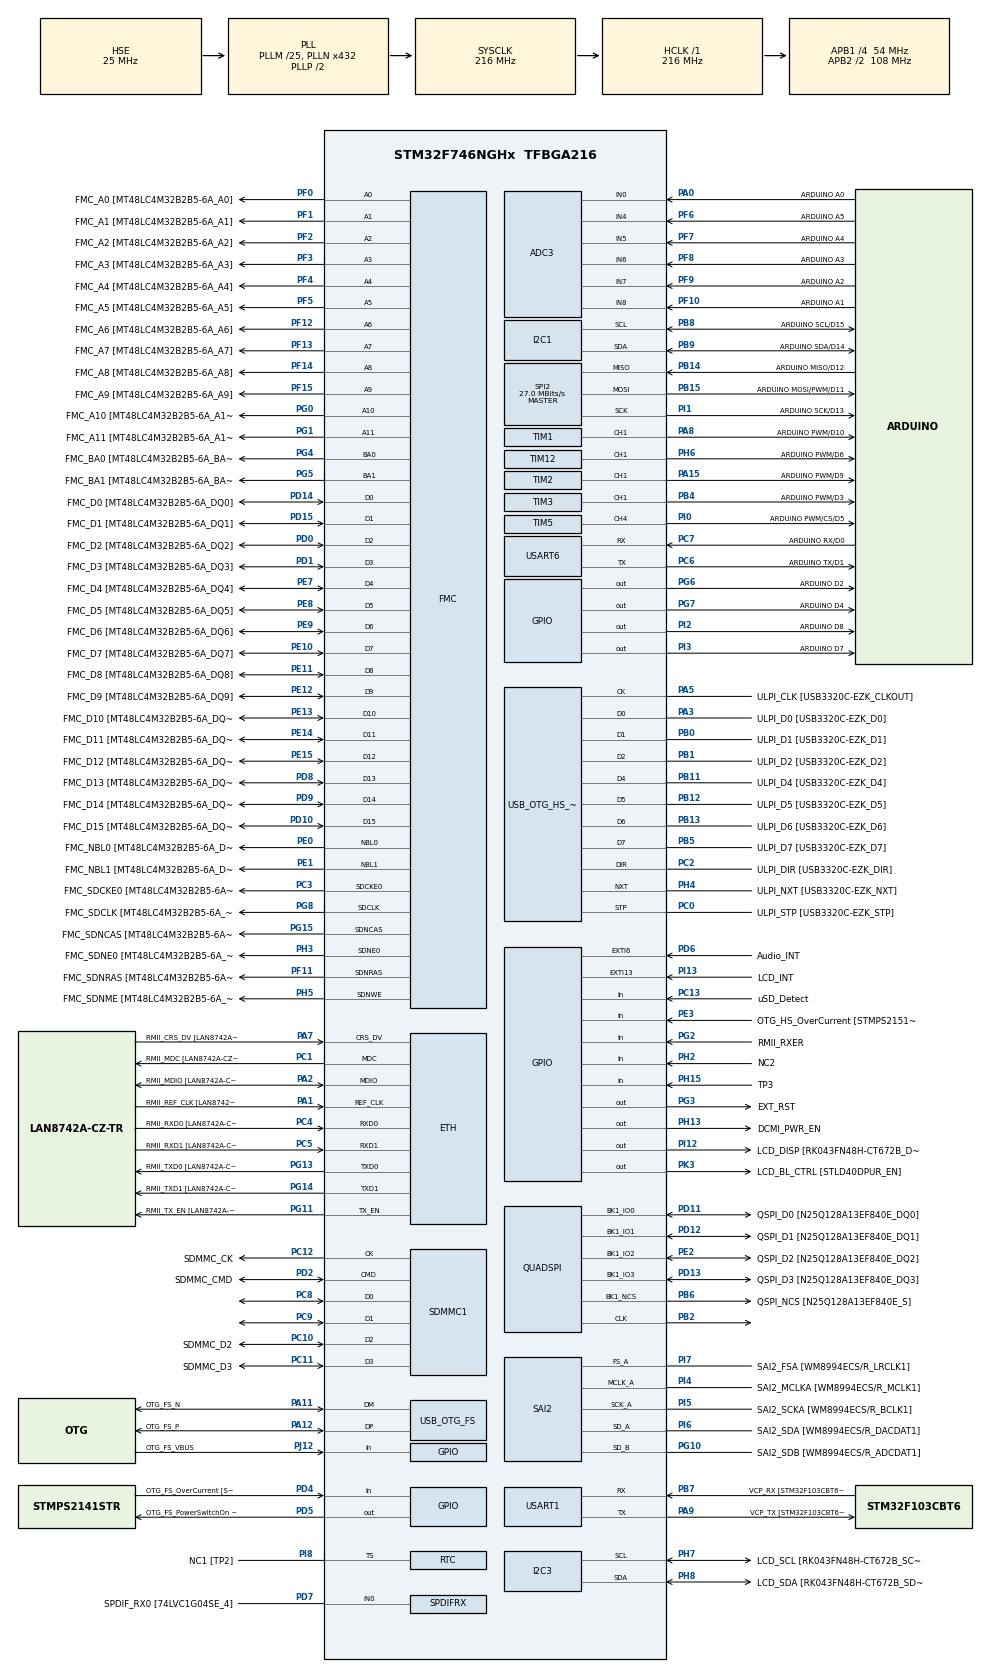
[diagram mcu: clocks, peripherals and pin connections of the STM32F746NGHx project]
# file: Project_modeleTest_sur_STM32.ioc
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ADC3.Channel=ADC_CHANNEL_7
ADC3.Channel-0\#ChannelRegularConversion=ADC_CHANNEL_4
ADC3.Channel-IN0=ADC_CHANNEL_0
ADC3.Channel-IN4=ADC_CHANNEL_4
ADC3.Channel-IN5=ADC_CHANNEL_5
ADC3.Channel-IN6=ADC_CHANNEL_6
ADC3.Channel-IN7=ADC_CHANNEL_7
ADC3.Channel-IN8=ADC_CHANNEL_8
CORTEX_M7.ART_ACCELERATOR_ENABLE=1
CORTEX_M7.CPU_DCache=Enabled
CORTEX_M7.CPU_ICache=Enabled
ETH.MediaInterface=HAL_ETH_RMII_MODE
ETH.PHY_Name=LAN8742A_PHY_ADDRESS
ETH.PHY_RESET_DELAY=0x00000FFF
ETH.PhyAddress=0
FATFS.BSP.number=1
FATFS0.BSP.STBoard=false
FATFS0.BSP.api=Unknown
FATFS0.BSP.instance=PC13
FATFS0.BSP.ip=GPIO
FATFS0.BSP.mode=Input
FATFS0.BSP.name=Detect_SDIO
FATFS0.BSP.solution=PC13
FMC.CASLatency1=FMC_SDRAM_CAS_LATENCY_3
FMC.ExitSelfRefreshDelay1=7
FMC.LoadToActiveDelay1=2
FMC.RCDDelay1=2
FMC.RPDelay1=2
FMC.RPDelay2=2
FMC.ReadBurst1=FMC_SDRAM_RBURST_ENABLE
FMC.ReadBurst2=FMC_SDRAM_RBURST_ENABLE
FMC.RowCycleDelay1=7
FMC.RowCycleDelay2=7
FMC.SDClockPeriod1=FMC_SDRAM_CLOCK_PERIOD_2
FMC.SDClockPeriod2=FMC_SDRAM_CLOCK_PERIOD_2
FMC.SelfRefreshTime1=4
FMC.WriteRecoveryTime1=3
FREERTOS.Tasks01=defaultTask,0,4096,StartDefaultTask,Default,NULL,Dynamic,NULL,NULL
FREERTOS.configCHECK_FOR_STACK_OVERFLOW=2
FREERTOS.configTOTAL_HEAP_SIZE=32768
FREERTOS.configUSE_APPLICATION_TASK_TAG=1
FREERTOS.configUSE_COUNTING_SEMAPHORES=1
FREERTOS.configUSE_IDLE_HOOK=1
FREERTOS.configUSE_MALLOC_FAILED_HOOK=1
FREERTOS.configUSE_NEWLIB_REENTRANT=0
FREERTOS.configUSE_RECURSIVE_MUTEXES=1
I2C1.Timing=0x20404768
I2C3.Timing=0x20404768
Mcu.Family=STM32F7
Mcu.Name=STM32F746NGHx
Mcu.Package=TFBGA216
NVIC.DMA2D_IRQn=true\:5\:0\:false\:false\:true\:true\:true\:true\:true
NVIC.OTG_FS_IRQn=true\:5\:0\:false\:false\:true\:true\:true\:true\:true
NVIC.PriorityGroup=NVIC_PRIORITYGROUP_4
NVIC.TIM6_DAC_IRQn=true\:0\:0\:false\:false\:true\:false\:false\:true\:true
NVIC.TimeBase=TIM6_DAC_IRQn
NVIC.TimeBaseIP=TIM6
PA0/WKUP.GPIO_Label=ARDUINO A0
PA0/WKUP.GPIO_Mode=GPIO_MODE_ANALOG
PA0/WKUP.GPIO_PuPd=GPIO_NOPULL
PA0/WKUP.Signal=ADCx_IN0
PA1.GPIO_Label=RMII_REF_CLK [LAN8742A-CZ-TR_REFCLK0]
PA1.Mode=RMII
PA1.Signal=ETH_REF_CLK
PA10.GPIO_Label=OTG_FS_ID
PA10.Signal=USB_OTG_FS_ID
PA11.GPIO_Label=OTG_FS_N
PA11.Mode=Host_Only
PA11.Signal=USB_OTG_FS_DM
PA12.GPIO_Label=OTG_FS_P
PA12.Mode=Host_Only
PA12.Signal=USB_OTG_FS_DP
PA13.GPIO_Label=SWDIO
PA13.Mode=Serial_Wire
PA13.Signal=SYS_JTMS-SWDIO
PA14.GPIO_Label=SWCLK
PA14.Mode=Serial_Wire
PA14.Signal=SYS_JTCK-SWCLK
PA15.GPIO_Label=ARDUINO PWM/D9
PA15.GPIO_ModeDefaultPP=GPIO_MODE_AF_PP
PA15.GPIO_PuPd=GPIO_NOPULL
PA15.GPIO_Speed=GPIO_SPEED_FREQ_LOW
PA15.Signal=S_TIM2_CH1_ETR
PA2.GPIO_Label=RMII_MDIO [LAN8742A-CZ-TR_MDIO]
PA2.Mode=RMII
PA2.Signal=ETH_MDIO
PA3.GPIO_Label=ULPI_D0 [USB3320C-EZK_D0]
PA3.Mode=Host_HS
PA3.Signal=USB_OTG_HS_ULPI_D0
PA4.GPIO_Label=DCMI_HSYNC
PA4.Signal=DCMI_HSYNC
PA5.GPIO_Label=ULPI_CLK [USB3320C-EZK_CLKOUT]
PA5.Mode=Host_HS
PA5.Signal=USB_OTG_HS_ULPI_CK
PA6.Signal=DCMI_PIXCLK
PA7.GPIO_Label=RMII_CRS_DV [LAN8742A-CZ-TR_CRS_DV]
PA7.Mode=RMII
PA7.Signal=ETH_CRS_DV
PA8.GPIO_Label=ARDUINO PWM/D10
PA8.GPIO_ModeDefaultPP=GPIO_MODE_AF_PP
PA8.GPIO_PuPd=GPIO_NOPULL
PA8.GPIO_Speed=GPIO_SPEED_FREQ_LOW
PA8.Signal=S_TIM1_CH1
PA9.GPIO_Label=VCP_TX [STM32F103CBT6_PA3]
PA9.GPIO_Mode=GPIO_MODE_AF_PP
PA9.GPIO_PuPd=GPIO_NOPULL
PA9.GPIO_Speed=GPIO_SPEED_FREQ_LOW
PA9.Mode=Asynchronous
PA9.Signal=USART1_TX
PB0.GPIO_Label=ULPI_D1 [USB3320C-EZK_D1]
PB0.Mode=Host_HS
PB0.Signal=USB_OTG_HS_ULPI_D1
PB1.GPIO_Label=ULPI_D2 [USB3320C-EZK_D2]
PB1.Mode=Host_HS
PB1.Signal=USB_OTG_HS_ULPI_D2
PB10.GPIO_Label=ULPI_D3 [USB3320C-EZK_D3]
PB10.Signal=USB_OTG_HS_ULPI_D3
PB11.GPIO_Label=ULPI_D4 [USB3320C-EZK_D4]
PB11.Mode=Host_HS
PB11.Signal=USB_OTG_HS_ULPI_D4
PB12.GPIO_Label=ULPI_D5 [USB3320C-EZK_D5]
PB12.Mode=Host_HS
PB12.Signal=USB_OTG_HS_ULPI_D5
PB13.GPIO_Label=ULPI_D6 [USB3320C-EZK_D6]
PB13.Mode=Host_HS
PB13.Signal=USB_OTG_HS_ULPI_D6
PB14.GPIO_Label=ARDUINO MISO/D12
PB14.GPIO_Mode=GPIO_MODE_AF_PP
PB14.GPIO_PuPd=GPIO_NOPULL
PB14.GPIO_Speed=GPIO_SPEED_FREQ_LOW
PB14.Mode=Full_Duplex_Master
PB14.Signal=SPI2_MISO
PB15.GPIO_Label=ARDUINO MOSI/PWM/D11
PB15.GPIO_Mode=GPIO_MODE_AF_PP
PB15.GPIO_PuPd=GPIO_NOPULL
PB15.GPIO_Speed=GPIO_SPEED_FREQ_LOW
PB15.Mode=Full_Duplex_Master
PB15.Signal=SPI2_MOSI
PB2.Mode=Single Bank 1
PB2.Signal=QUADSPI_CLK
PB3.GPIO_Label=SWO
PB3.Signal=SYS_JTDO-SWO
PB4.GPIO_Label=ARDUINO PWM/D3
PB4.GPIO_ModeDefaultPP=GPIO_MODE_AF_PP
PB4.GPIO_PuPd=GPIO_NOPULL
PB4.GPIO_Speed=GPIO_SPEED_FREQ_LOW
PB4.Signal=S_TIM3_CH1
PB5.GPIO_Label=ULPI_D7 [USB3320C-EZK_D7]
PB5.Mode=Host_HS
PB5.Signal=USB_OTG_HS_ULPI_D7
PB6.GPIO_Label=QSPI_NCS [N25Q128A13EF840E_S]
PB6.Mode=Single Bank 1
PB6.Signal=QUADSPI_BK1_NCS
PB7.GPIO_Label=VCP_RX [STM32F103CBT6_PA2]
PB7.GPIO_Mode=GPIO_MODE_AF_PP
PB7.GPIO_PuPd=GPIO_NOPULL
PB7.GPIO_Speed=GPIO_SPEED_FREQ_LOW
PB7.Mode=Asynchronous
PB7.Signal=USART1_RX
PB8.GPIO_Label=ARDUINO SCL/D15
PB8.GPIO_Mode=GPIO_MODE_AF_OD
PB8.GPIO_Pu=GPIO_PULLUP
PB8.GPIO_PuPd=GPIO_NOPULL
PB8.GPIO_Speed=GPIO_SPEED_FREQ_LOW
PB8.Mode=I2C
PB8.Signal=I2C1_SCL
PB9.GPIO_Label=ARDUINO SDA/D14
PB9.GPIO_Mode=GPIO_MODE_AF_OD
PB9.GPIO_Pu=GPIO_PULLUP
PB9.GPIO_PuPd=GPIO_NOPULL
PB9.GPIO_Speed=GPIO_SPEED_FREQ_LOW
PB9.Mode=I2C
PB9.Signal=I2C1_SDA
PC0.GPIO_Label=ULPI_STP [USB3320C-EZK_STP]
PC0.Mode=Host_HS
PC0.Signal=USB_OTG_HS_ULPI_STP
PC1.GPIO_Label=RMII_MDC [LAN8742A-CZ-TR_MDC]
PC1.Mode=RMII
PC1.Signal=ETH_MDC
PC10.GPIO_Label=SDMMC_D2
PC10.Mode=SD_4_bits_Wide_bus
PC10.Signal=SDMMC1_D2
PC11.GPIO_Label=SDMMC_D3
PC11.Mode=SD_4_bits_Wide_bus
PC11.Signal=SDMMC1_D3
PC12.GPIO_Label=SDMMC_CK
PC12.Mode=SD_4_bits_Wide_bus
PC12.Signal=SDMMC1_CK
PC13.GPIO_Label=uSD_Detect
PC13.Signal=GPIO_Input
PC14/OSC32_IN.GPIO_Label=RCC_OSC32_IN
PC14/OSC32_IN.Mode=LSE-External-Oscillator
PC14/OSC32_IN.Signal=RCC_OSC32_IN
PC15/OSC32_OUT.GPIO_Label=RCC_OSC32_OUT
PC15/OSC32_OUT.Mode=LSE-External-Oscillator
PC15/OSC32_OUT.Signal=RCC_OSC32_OUT
PC2.GPIO_Label=ULPI_DIR [USB3320C-EZK_DIR]
PC2.Mode=Host_HS
PC2.Signal=USB_OTG_HS_ULPI_DIR
PC3.GPIO_Label=FMC_SDCKE0 [MT48LC4M32B2B5-6A_CKE]
PC3.Mode=SdramChipSelect1_1
PC3.Signal=FMC_SDCKE0
PC4.GPIO_Label=RMII_RXD0 [LAN8742A-CZ-TR_RXD0]
PC4.Mode=RMII
PC4.Signal=ETH_RXD0
PC5.GPIO_Label=RMII_RXD1 [LAN8742A-CZ-TR_RXD1]
PC5.Mode=RMII
PC5.Signal=ETH_RXD1
PC6.GPIO_Label=ARDUINO TX/D1
PC6.Mode=Asynchronous
PC6.Signal=USART6_TX
PC7.GPIO_Label=ARDUINO RX/D0
PC7.Mode=Asynchronous
PC7.Signal=USART6_RX
PC8.Mode=SD_4_bits_Wide_bus
PC8.Signal=SDMMC1_D0
PC9.Mode=SD_4_bits_Wide_bus
PC9.Signal=SDMMC1_D1
PD0.GPIO_Label=FMC_D2 [MT48LC4M32B2B5-6A_DQ2]
PD0.Signal=FMC_D2_DA2
PD1.GPIO_Label=FMC_D3 [MT48LC4M32B2B5-6A_DQ3]
PD1.Signal=FMC_D3_DA3
PD10.GPIO_Label=FMC_D15 [MT48LC4M32B2B5-6A_DQ15]
PD10.Signal=FMC_D15_DA15
PD11.GPIO_Label=QSPI_D0 [N25Q128A13EF840E_DQ0]
PD11.Mode=Single Bank 1
PD11.Signal=QUADSPI_BK1_IO0
PD12.GPIO_Label=QSPI_D1 [N25Q128A13EF840E_DQ1]
PD12.Mode=Single Bank 1
PD12.Signal=QUADSPI_BK1_IO1
PD13.GPIO_Label=QSPI_D3 [N25Q128A13EF840E_DQ3]
PD13.Mode=Single Bank 1
PD13.Signal=QUADSPI_BK1_IO3
PD14.GPIO_Label=FMC_D0 [MT48LC4M32B2B5-6A_DQ0]
PD14.Signal=FMC_D0_DA0
PD15.GPIO_Label=FMC_D1 [MT48LC4M32B2B5-6A_DQ1]
PD15.Signal=FMC_D1_DA1
PD2.GPIO_Label=SDMMC_CMD
PD2.Mode=SD_4_bits_Wide_bus
PD2.Signal=SDMMC1_CMD
PD3.GPIO_Label=DCMI_D5
PD3.Signal=DCMI_D5
PD4.GPIO_Label=OTG_FS_OverCurrent [STMPS2141STR_Fault]
PD4.Signal=GPIO_Input
PD5.GPIO_Label=OTG_FS_PowerSwitchOn [STMPS2141STR_EN]
PD5.PinState=GPIO_PIN_SET
PD5.Signal=GPIO_Output
PD6.GPIO_Label=Audio_INT
PD6.GPIO_ModeDefaultEXTI=GPIO_MODE_EVT_RISING
PD6.Signal=GPXTI6
PD7.GPIO_Label=SPDIF_RX0 [74LVC1G04SE_4]
PD7.Mode=IN0
PD7.Signal=SPDIFRX_IN0
PD8.GPIO_Label=FMC_D13 [MT48LC4M32B2B5-6A_DQ13]
PD8.Signal=FMC_D13_DA13
PD9.GPIO_Label=FMC_D14 [MT48LC4M32B2B5-6A_DQ14]
PD9.Signal=FMC_D14_DA14
PE0.GPIO_Label=FMC_NBL0 [MT48LC4M32B2B5-6A_DQM0]
PE0.Signal=FMC_NBL0
PE1.GPIO_Label=FMC_NBL1 [MT48LC4M32B2B5-6A_DQM1]
PE1.Signal=FMC_NBL1
PE10.GPIO_Label=FMC_D7 [MT48LC4M32B2B5-6A_DQ7]
PE10.Signal=FMC_D7_DA7
PE11.GPIO_Label=FMC_D8 [MT48LC4M32B2B5-6A_DQ8]
PE11.Signal=FMC_D8_DA8
PE12.GPIO_Label=FMC_D9 [MT48LC4M32B2B5-6A_DQ9]
PE12.Signal=FMC_D9_DA9
PE13.GPIO_Label=FMC_D10 [MT48LC4M32B2B5-6A_DQ10]
PE13.Signal=FMC_D10_DA10
PE14.GPIO_Label=FMC_D11 [MT48LC4M32B2B5-6A_DQ11]
PE14.Signal=FMC_D11_DA11
PE15.GPIO_Label=FMC_D12 [MT48LC4M32B2B5-6A_DQ12]
PE15.Signal=FMC_D12_DA12
PE2.GPIO_Label=QSPI_D2 [N25Q128A13EF840E_DQ2]
PE2.Mode=Single Bank 1
PE2.Signal=QUADSPI_BK1_IO2
PE3.GPIO_Label=OTG_HS_OverCurrent [STMPS2151STR_FAULT]
PE3.Signal=GPIO_Input
PE4.GPIO_Label=LCD_B0 [RK043FN48H-CT672B_B0]
PE4.Signal=LTDC_B0
PE5.GPIO_Label=DCMI_D6
PE5.Signal=DCMI_D6
PE6.GPIO_Label=DCMI_D7
PE6.Signal=DCMI_D7
PE7.GPIO_Label=FMC_D4 [MT48LC4M32B2B5-6A_DQ4]
PE7.Signal=FMC_D4_DA4
PE8.GPIO_Label=FMC_D5 [MT48LC4M32B2B5-6A_DQ5]
PE8.Signal=FMC_D5_DA5
PE9.GPIO_Label=FMC_D6 [MT48LC4M32B2B5-6A_DQ6]
PE9.Signal=FMC_D6_DA6
PF0.GPIO_Label=FMC_A0 [MT48LC4M32B2B5-6A_A0]
PF0.Signal=FMC_A0
PF1.GPIO_Label=FMC_A1 [MT48LC4M32B2B5-6A_A1]
PF1.Signal=FMC_A1
PF10.GPIO_Label=ARDUINO A1
PF10.GPIO_Mode=GPIO_MODE_ANALOG
PF10.GPIO_PuPd=GPIO_NOPULL
PF10.Mode=IN8
PF10.Signal=ADC3_IN8
PF11.GPIO_Label=FMC_SDNRAS [MT48LC4M32B2B5-6A_RAS]
PF11.Signal=FMC_SDNRAS
PF12.GPIO_Label=FMC_A6 [MT48LC4M32B2B5-6A_A6]
PF12.Signal=FMC_A6
PF13.GPIO_Label=FMC_A7 [MT48LC4M32B2B5-6A_A7]
PF13.Signal=FMC_A7
PF14.GPIO_Label=FMC_A8 [MT48LC4M32B2B5-6A_A8]
PF14.Signal=FMC_A8
PF15.GPIO_Label=FMC_A9 [MT48LC4M32B2B5-6A_A9]
PF15.Signal=FMC_A9
PF2.GPIO_Label=FMC_A2 [MT48LC4M32B2B5-6A_A2]
PF2.Signal=FMC_A2
PF3.GPIO_Label=FMC_A3 [MT48LC4M32B2B5-6A_A3]
PF3.Signal=FMC_A3
PF4.GPIO_Label=FMC_A4 [MT48LC4M32B2B5-6A_A4]
PF4.Signal=FMC_A4
PF5.GPIO_Label=FMC_A5 [MT48LC4M32B2B5-6A_A5]
PF5.Signal=FMC_A5
PF6.GPIO_Label=ARDUINO A5
PF6.GPIO_Mode=GPIO_MODE_ANALOG
PF6.GPIO_PuPd=GPIO_NOPULL
PF6.Mode=IN4
PF6.Signal=ADC3_IN4
PF7.GPIO_Label=ARDUINO A4
PF7.GPIO_Mode=GPIO_MODE_ANALOG
PF7.GPIO_PuPd=GPIO_NOPULL
PF7.Mode=IN5
PF7.Signal=ADC3_IN5
PF8.GPIO_Label=ARDUINO A3
PF8.GPIO_Mode=GPIO_MODE_ANALOG
PF8.GPIO_PuPd=GPIO_NOPULL
PF8.Mode=IN6
PF8.Signal=ADC3_IN6
PF9.GPIO_Label=ARDUINO A2
PF9.GPIO_Mode=GPIO_MODE_ANALOG
PF9.GPIO_PuPd=GPIO_NOPULL
PF9.Mode=IN7
PF9.Signal=ADC3_IN7
PG0.GPIO_Label=FMC_A10 [MT48LC4M32B2B5-6A_A10]
PG0.Signal=FMC_A10
PG1.GPIO_Label=FMC_A11 [MT48LC4M32B2B5-6A_A11]
PG1.Signal=FMC_A11
PG10.GPIO_Label=SAI2_SDB [WM8994ECS/R_ADCDAT1]
PG10.Mode=SAI_B_SyncSlave
PG10.Signal=SAI2_SD_B
PG11.GPIO_Label=RMII_TX_EN [LAN8742A-CZ-TR_TXEN]
PG11.Mode=RMII
PG11.Signal=ETH_TX_EN
PG12.GPIO_Label=LCD_B4 [RK043FN48H-CT672B_B4]
PG12.Signal=LTDC_B4
PG13.GPIO_Label=RMII_TXD0 [LAN8742A-CZ-TR_TXD0]
PG13.Mode=RMII
PG13.Signal=ETH_TXD0
PG14.GPIO_Label=RMII_TXD1 [LAN8742A-CZ-TR_TXD1]
PG14.Mode=RMII
PG14.Signal=ETH_TXD1
PG15.GPIO_Label=FMC_SDNCAS [MT48LC4M32B2B5-6A_CAS]
PG15.Signal=FMC_SDNCAS
PG2.GPIO_Label=RMII_RXER
PG2.Signal=GPIO_Input
PG3.GPIO_Label=EXT_RST
PG3.Signal=GPIO_Output
PG4.GPIO_Label=FMC_BA0 [MT48LC4M32B2B5-6A_BA0]
PG4.Signal=FMC_A14_BA0
PG5.GPIO_Label=FMC_BA1 [MT48LC4M32B2B5-6A_BA1]
PG5.Signal=FMC_A15_BA1
PG6.GPIO_Label=ARDUINO D2
PG6.Signal=GPIO_Output
PG7.GPIO_Label=ARDUINO D4
PG7.Signal=GPIO_Output
PG8.GPIO_Label=FMC_SDCLK [MT48LC4M32B2B5-6A_CLK]
PG8.Signal=FMC_SDCLK
PG9.GPIO_Label=DCMI_VSYNC
PG9.Signal=DCMI_VSYNC
PH0/OSC_IN.GPIO_Label=OSC_25M [NZ2520SB-25.00M_OUT]
PH0/OSC_IN.Mode=HSE-External-Oscillator
PH0/OSC_IN.Signal=RCC_OSC_IN
PH1/OSC_OUT.Mode=HSE-External-Oscillator
PH1/OSC_OUT.Signal=RCC_OSC_OUT
PH10.GPIO_Label=DCMI_D1
PH10.Signal=DCMI_D1
PH11.GPIO_Label=DCMI_D2
PH11.Signal=DCMI_D2
PH12.GPIO_Label=DCMI_D3
PH12.Signal=DCMI_D3
PH13.GPIO_Label=DCMI_PWR_EN
PH13.Signal=GPIO_Output
PH14.GPIO_Label=DCMI_D4
PH14.Signal=DCMI_D4
PH15.GPIO_Label=TP3
PH15.Signal=GPIO_Input
PH2.GPIO_Label=NC2
PH2.Signal=GPIO_Input
PH3.GPIO_Label=FMC_SDNE0 [MT48LC4M32B2B5-6A_CS]
PH3.Mode=SdramChipSelect1_1
PH3.Signal=FMC_SDNE0
PH4.GPIO_Label=ULPI_NXT [USB3320C-EZK_NXT]
PH4.Mode=Host_HS
PH4.Signal=USB_OTG_HS_ULPI_NXT
PH5.GPIO_Label=FMC_SDNME [MT48LC4M32B2B5-6A_WE]
PH5.Signal=FMC_SDNWE
PH6.GPIO_Label=ARDUINO PWM/D6
PH6.Signal=S_TIM12_CH1
PH7.GPIO_Label=LCD_SCL [RK043FN48H-CT672B_SCL]
PH7.GPIO_Pu=GPIO_PULLUP
PH7.Mode=I2C
PH7.Signal=I2C3_SCL
PH8.GPIO_Label=LCD_SDA [RK043FN48H-CT672B_SDA]
PH8.GPIO_Pu=GPIO_PULLUP
PH8.Mode=I2C
PH8.Signal=I2C3_SDA
PH9.GPIO_Label=DCMI_D0
PH9.Signal=DCMI_D0
PI0.GPIO_Label=ARDUINO PWM/CS/D5
PI0.GPIO_ModeDefaultPP=GPIO_MODE_AF_PP
PI0.GPIO_PuPd=GPIO_NOPULL
PI0.GPIO_Speed=GPIO_SPEED_FREQ_LOW
PI0.Signal=S_TIM5_CH4
PI1.GPIO_Label=ARDUINO SCK/D13
PI1.GPIO_Mode=GPIO_MODE_AF_PP
PI1.GPIO_PuPd=GPIO_NOPULL
PI1.GPIO_Speed=GPIO_SPEED_FREQ_LOW
PI1.Mode=Full_Duplex_Master
PI1.Signal=SPI2_SCK
PI10.GPIO_Label=LCD_HSYNC [RK043FN48H-CT672B_HSYNC]
PI10.Signal=LTDC_HSYNC
PI12.GPIO_Label=LCD_DISP [RK043FN48H-CT672B_DISP] 
PI12.PinState=GPIO_PIN_SET
PI12.Signal=GPIO_Output
PI13.GPIO_Label=LCD_INT
PI13.GPIO_ModeDefaultEXTI=GPIO_MODE_EVT_RISING
PI13.Signal=GPXTI13
PI14.GPIO_Label=LCD_CLK [RK043FN48H-CT672B_CLK]
PI14.Signal=LTDC_CLK
PI15.GPIO_Label=LCD_R0 [RK043FN48H-CT672B_R0]
PI15.Signal=LTDC_R0
PI2.GPIO_Label=ARDUINO D8
PI2.Signal=GPIO_Output
PI3.GPIO_Label=ARDUINO D7
PI3.Signal=GPIO_Output
PI4.GPIO_Label=SAI2_MCLKA [WM8994ECS/R_MCLK1]
PI4.Mode=SAI_A_MasterWithClock
PI4.Signal=SAI2_MCLK_A
PI5.GPIO_Label=SAI2_SCKA [WM8994ECS/R_BCLK1]
PI5.Mode=SAI_A_MasterWithClock
PI5.Signal=SAI2_SCK_A
PI6.GPIO_Label=SAI2_SDA [WM8994ECS/R_DACDAT1]
PI6.Mode=SAI_A_MasterWithClock
PI6.Signal=SAI2_SD_A
PI7.GPIO_Label=SAI2_FSA [WM8994ECS/R_LRCLK1]
PI7.Mode=SAI_A_MasterWithClock
PI7.Signal=SAI2_FS_A
PI8.GPIO_Label=NC1 [TP2]
PI8.Mode=Timestamp enabled - Input Enabled to TS
PI8.Signal=RTC_TS
PI9.GPIO_Label=LCD_VSYNC [RK043FN48H-CT672B_VSYNC]
PI9.Signal=LTDC_VSYNC
PJ0.GPIO_Label=LCD_R1 [RK043FN48H-CT672B_R1]
PJ0.Signal=LTDC_R1
PJ1.GPIO_Label=LCD_R2 [RK043FN48H-CT672B_R2]
PJ1.Signal=LTDC_R2
PJ10.GPIO_Label=LCD_G3 [RK043FN48H-CT672B_G3]
PJ10.Signal=LTDC_G3
PJ11.GPIO_Label=LCD_G4 [RK043FN48H-CT672B_G4]
PJ11.Signal=LTDC_G4
PJ12.GPIO_Label=OTG_FS_VBUS
PJ12.Signal=GPIO_Input
PJ13.GPIO_Label=LCD_B1 [RK043FN48H-CT672B_B1]
PJ13.Signal=LTDC_B1
PJ14.GPIO_Label=LCD_B2 [RK043FN48H-CT672B_B2]
PJ14.Signal=LTDC_B2
PJ15.GPIO_Label=LCD_B3 [RK043FN48H-CT672B_B3]
PJ15.Signal=LTDC_B3
PJ2.GPIO_Label=LCD_R3 [RK043FN48H-CT672B_R3]
PJ2.Signal=LTDC_R3
PJ3.GPIO_Label=LCD_R4 [RK043FN48H-CT672B_R4]
PJ3.Signal=LTDC_R4
PJ4.GPIO_Label=LCD_R5 [RK043FN48H-CT672B_R5]
PJ4.Signal=LTDC_R5
PJ5.GPIO_Label=LCD_R6 [RK043FN48H-CT672B_R6]
PJ5.Signal=LTDC_R6
PJ6.GPIO_Label=LCD_R7 [RK043FN48H-CT672B_R7]
PJ6.Signal=LTDC_R7
PJ7.GPIO_Label=LCD_G0 [RK043FN48H-CT672B_G0]
PJ7.Signal=LTDC_G0
PJ8.GPIO_Label=LCD_G1 [RK043FN48H-CT672B_G1]
PJ8.Signal=LTDC_G1
PJ9.GPIO_Label=LCD_G2 [RK043FN48H-CT672B_G2]
PJ9.Signal=LTDC_G2
PK0.GPIO_Label=LCD_G5 [RK043FN48H-CT672B_G5]
PK0.Signal=LTDC_G5
PK1.GPIO_Label=LCD_G6 [RK043FN48H-CT672B_G6]
PK1.Signal=LTDC_G6
PK2.GPIO_Label=LCD_G7 [RK043FN48H-CT672B_G7]
PK2.Signal=LTDC_G7
PK3.GPIO_Label=LCD_BL_CTRL [STLD40DPUR_EN]
PK3.GPIO_Speed=GPIO_SPEED_FREQ_LOW
PK3.PinState=GPIO_PIN_SET
PK3.Signal=GPIO_Output
PK4.GPIO_Label=LCD_B5 [RK043FN48H-CT672B_B5]
PK4.Signal=LTDC_B5
PK5.GPIO_Label=LCD_B6 [RK043FN48H-CT672B_B6]
PK5.Signal=LTDC_B6
PK6.GPIO_Label=LCD_B7 [RK043FN48H-CT672B_B7]
PK6.Signal=LTDC_B7
PK7.GPIO_Label=LCD_DE [RK043FN48H-CT672B_DE]
PK7.Signal=LTDC_DE
ProjectManager.HeapSize=0x2000
ProjectManager.StackSize=0x800
ProjectManager.TargetToolchain=STM32CubeIDE
QUADSPI.ChipSelectHighTime=QSPI_CS_HIGH_TIME_6_CYCLE
QUADSPI.ClockPrescaler=1
QUADSPI.FifoThreshold=4
QUADSPI.FlashSize=24
QUADSPI.SampleShifting=QSPI_SAMPLE_SHIFTING_HALFCYCLE
RCC.AHBFreq_Value=216000000
RCC.APB1CLKDivider=RCC_HCLK_DIV4
RCC.APB1Freq_Value=54000000
RCC.APB1TimFreq_Value=108000000
RCC.APB2CLKDivider=RCC_HCLK_DIV2
RCC.APB2Freq_Value=108000000
RCC.APB2TimFreq_Value=216000000
RCC.CortexFreq_Value=216000000
RCC.HCLKFreq_Value=216000000
RCC.HSE_VALUE=25000000
RCC.HSI_VALUE=16000000
RCC.PLL48CLockSelection=RCC_CLK48SOURCE_PLLSAIP
RCC.PLLI2SN=100
RCC.PLLM=25
RCC.PLLN=432
RCC.PLLP=2
RCC.PLLQ=9
RCC.PLLSAIN=384
RCC.PLLSAIP=RCC_PLLSAIP_DIV8
RCC.PLLSAIR=5
RCC.PLLSAIRDiv=RCC_PLLSAIDIVR_8
RCC.SDMMCClockSelection=RCC_SDMMC1CLKSOURCE_CLK48
RCC.SYSCLKFreq_VALUE=216000000
RCC.SYSCLKSource=RCC_SYSCLKSOURCE_PLLCLK
RCC.USBFreq_Value=48000000
RCC.VCOOutputFreq_Value=432000000
RTC.Alarm-Alarm\ A=RTC_ALARM_A
RTC.Alarm_B-Alarm\ B=RTC_ALARM_B
SAI2.ErrorAudioFreq-SAI_A_MasterWithClock=-2.34 %
SAI2.Instance-SAI_A_MasterWithClock=SAI$Index_Block_A
SAI2.Instance-SAI_B_SyncSlave=SAI$Index_Block_B
SAI2.MClockEnable-SAI_A_MasterWithClock=SAI_MASTERCLOCK_ENABLE
SAI2.RealAudioFreq-SAI_A_MasterWithClock=187.5 KHz
SAI2.Synchro-SAI_B_SyncSlave=SAI_SYNCHRONOUS
SAI2.VirtualMode-SAI_A_MasterWithClock=VM_MASTER
SAI2.VirtualMode-SAI_B_SyncSlave=VM_SLAVE
SDMMC1.WideMode=SDMMC_BUS_WIDE_4B
SH.ADCx_IN0.0=ADC3_IN0,IN0
SH.FMC_A0.0=FMC_A0,12b-sda1
SH.FMC_A1.0=FMC_A1,12b-sda1
SH.FMC_A10.0=FMC_A10,12b-sda1
SH.FMC_A11.0=FMC_A11,12b-sda1
SH.FMC_A14_BA0.0=FMC_BA0,FourSdramBanks1
SH.FMC_A15_BA1.0=FMC_BA1,FourSdramBanks1
SH.FMC_A2.0=FMC_A2,12b-sda1
SH.FMC_A3.0=FMC_A3,12b-sda1
SH.FMC_A4.0=FMC_A4,12b-sda1
SH.FMC_A5.0=FMC_A5,12b-sda1
SH.FMC_A6.0=FMC_A6,12b-sda1
SH.FMC_A7.0=FMC_A7,12b-sda1
SH.FMC_A8.0=FMC_A8,12b-sda1
SH.FMC_A9.0=FMC_A9,12b-sda1
SH.FMC_D0_DA0.0=FMC_D0,sd-16b-d1
SH.FMC_D10_DA10.0=FMC_D10,sd-16b-d1
SH.FMC_D11_DA11.0=FMC_D11,sd-16b-d1
SH.FMC_D12_DA12.0=FMC_D12,sd-16b-d1
SH.FMC_D13_DA13.0=FMC_D13,sd-16b-d1
SH.FMC_D14_DA14.0=FMC_D14,sd-16b-d1
SH.FMC_D15_DA15.0=FMC_D15,sd-16b-d1
SH.FMC_D1_DA1.0=FMC_D1,sd-16b-d1
SH.FMC_D2_DA2.0=FMC_D2,sd-16b-d1
SH.FMC_D3_DA3.0=FMC_D3,sd-16b-d1
SH.FMC_D4_DA4.0=FMC_D4,sd-16b-d1
SH.FMC_D5_DA5.0=FMC_D5,sd-16b-d1
SH.FMC_D6_DA6.0=FMC_D6,sd-16b-d1
SH.FMC_D7_DA7.0=FMC_D7,sd-16b-d1
SH.FMC_D8_DA8.0=FMC_D8,sd-16b-d1
SH.FMC_D9_DA9.0=FMC_D9,sd-16b-d1
SH.FMC_NBL0.0=FMC_NBL0,Sd2ByteEnable1
SH.FMC_NBL1.0=FMC_NBL1,Sd2ByteEnable1
SH.FMC_SDCLK.0=FMC_SDCLK,12b-sda1
SH.FMC_SDNCAS.0=FMC_SDNCAS,12b-sda1
SH.FMC_SDNRAS.0=FMC_SDNRAS,12b-sda1
SH.FMC_SDNWE.0=FMC_SDNWE,12b-sda1
SH.S_TIM12_CH1.0=TIM12_CH1,PWM Generation1 CH1
SH.S_TIM1_CH1.0=TIM1_CH1,PWM Generation1 CH1
SH.S_TIM2_CH1_ETR.0=TIM2_CH1,PWM Generation1 CH1
SH.S_TIM3_CH1.0=TIM3_CH1,PWM Generation1 CH1
SH.S_TIM5_CH4.0=TIM5_CH4,PWM Generation4 CH4
SPI2.BaudRatePrescaler=SPI_BAUDRATEPRESCALER_2
SPI2.CalculateBaudRate=27.0 MBits/s
SPI2.Direction=SPI_DIRECTION_2LINES
SPI2.Mode=SPI_MODE_MASTER
SPI2.VirtualType=VM_MASTER
STMicroelectronics.X-CUBE-AI.7.3.0.ActivationBufferSizeList=28276
STMicroelectronics.X-CUBE-AI.7.3.0.ActivationBuffers=pool0
STMicroelectronics.X-CUBE-AI.7.3.0.ActivationNames=pool0
STMicroelectronics.X-CUBE-AI.7.3.0.ActivationSizes=AI_NETWORK_1_DATA_ACTIVATION_1_SIZE
STMicroelectronics.X-CUBE-AI.7.3.0.HeapSize=0x2000
STMicroelectronics.X-CUBE-AI.7.3.0.InternalRamActivationBufferMaxSize=AI_NETWORK_1_DATA_ACTIVATIONS_SIZE
STMicroelectronics.X-CUBE-AI.7.3.0.LatestDirectoryUsed-669d32e52d26e26a31a0dea2207ed3b73bd16a9ab170683de0b77e9fc4a6fd29=C\:\\Users\\Antoine.Z\\Downloads
STMicroelectronics.X-CUBE-AI.7.3.0.MaximumNumberOfInputLayer=1
STMicroelectronics.X-CUBE-AI.7.3.0.MaximumNumberOfOutputLayer=1
STMicroelectronics.X-CUBE-AI.7.3.0.MaximumSizeOfInputLayer=1
STMicroelectronics.X-CUBE-AI.7.3.0.MaximumSizeOfOutputLayer=1
STMicroelectronics.X-CUBE-AI.7.3.0.ModelActualCompression-669d32e52d26e26a31a0dea2207ed3b73bd16a9ab170683de0b77e9fc4a6fd29=7.88
STMicroelectronics.X-CUBE-AI.7.3.0.ModelCompression-669d32e52d26e26a31a0dea2207ed3b73bd16a9ab170683de0b77e9fc4a6fd29=High
STMicroelectronics.X-CUBE-AI.7.3.0.ModelFlashOccupation-669d32e52d26e26a31a0dea2207ed3b73bd16a9ab170683de0b77e9fc4a6fd29=396404
STMicroelectronics.X-CUBE-AI.7.3.0.ModelHashList=669d32e52d26e26a31a0dea2207ed3b73bd16a9ab170683de0b77e9fc4a6fd29
STMicroelectronics.X-CUBE-AI.7.3.0.ModelKind-669d32e52d26e26a31a0dea2207ed3b73bd16a9ab170683de0b77e9fc4a6fd29=KERAS
STMicroelectronics.X-CUBE-AI.7.3.0.ModelMacc-669d32e52d26e26a31a0dea2207ed3b73bd16a9ab170683de0b77e9fc4a6fd29=875232
STMicroelectronics.X-CUBE-AI.7.3.0.ModelName-669d32e52d26e26a31a0dea2207ed3b73bd16a9ab170683de0b77e9fc4a6fd29=network_1
STMicroelectronics.X-CUBE-AI.7.3.0.ModelNameList=network_1
STMicroelectronics.X-CUBE-AI.7.3.0.ModelRamOccupation-669d32e52d26e26a31a0dea2207ed3b73bd16a9ab170683de0b77e9fc4a6fd29=28276
STMicroelectronics.X-CUBE-AI.7.3.0.ModelStructureFile-669d32e52d26e26a31a0dea2207ed3b73bd16a9ab170683de0b77e9fc4a6fd29=C\:\\Users\\Antoine.Z\\Downloads\\model.h5
STMicroelectronics.X-CUBE-AI.7.3.0.ModelType-669d32e52d26e26a31a0dea2207ed3b73bd16a9ab170683de0b77e9fc4a6fd29=Saved model
STMicroelectronics.X-CUBE-AI.7.3.0.ReadyForCodeGeneration=true
STMicroelectronics.X-CUBE-AI.7.3.0.StackSize=0x800
STMicroelectronics.X-CUBE-AI.7.3.0.WorkingBufferStartAddrList=0xFFFFFFFF
STMicroelectronics.X-CUBE-AI.7.3.0.XAaCUBEAaAICcArtificialOoIntelligenceJjCore=true
STMicroelectronics.X-CUBE-AI.7.3.0.copyWeightToRam=false
STMicroelectronics.X-CUBE-AI.7.3.0.copyWeightToRam-669d32e52d26e26a31a0dea2207ed3b73bd16a9ab170683de0b77e9fc4a6fd29=false
STMicroelectronics.X-CUBE-AI.7.3.0.customLayerConfigEnabled=false
STMicroelectronics.X-CUBE-AI.7.3.0.customLayerConfigEnabled-669d32e52d26e26a31a0dea2207ed3b73bd16a9ab170683de0b77e9fc4a6fd29=false
STMicroelectronics.X-CUBE-AI.7.3.0.useInputAllocation=true
STMicroelectronics.X-CUBE-AI.7.3.0.useInputAllocation-669d32e52d26e26a31a0dea2207ed3b73bd16a9ab170683de0b77e9fc4a6fd29=true
STMicroelectronics.X-CUBE-AI.7.3.0.useOutputAllocation=true
STMicroelectronics.X-CUBE-AI.7.3.0.useOutputAllocation-669d32e52d26e26a31a0dea2207ed3b73bd16a9ab170683de0b77e9fc4a6fd29=true
TIM1.Channel-PWM\ Generation1\ CH1=TIM_CHANNEL_1
TIM12.Channel-PWM\ Generation1\ CH1=TIM_CHANNEL_1
TIM2.Channel-PWM\ Generation1\ CH1=TIM_CHANNEL_1
TIM3.Channel-PWM\ Generation1\ CH1=TIM_CHANNEL_1
TIM5.Channel-PWM\ Generation4\ CH4=TIM_CHANNEL_4
USART1.VirtualMode-Asynchronous=VM_ASYNC
USART6.VirtualMode-Asynchronous=VM_ASYNC
USB_HOST.BSP.number=1
USB_HOST.USBH_HandleTypeDef-CDC_FS=hUsbHostFS
USB_HOST.VirtualModeFS=Cdc
USB_HOST0.BSP.STBoard=false
USB_HOST0.BSP.api=UnknownBspDriver
USB_HOST0.BSP.instance=PD5
USB_HOST0.BSP.ip=GPIO
USB_HOST0.BSP.mode=Output
USB_HOST0.BSP.name=Drive_VBUS_FS
USB_HOST0.BSP.solution=PD5
USB_OTG_FS.VirtualMode=Host_Only
USB_OTG_FS.phy_itface=HCD_PHY_EMBEDDED
VP_CRC_VS_CRC.Mode=CRC_Activate
VP_DMA2D_VS_DMA2D.Mode=DMA2D_Activate
VP_FATFS_VS_SDIO.Mode=SDIO
VP_FREERTOS_VS_CMSIS_V1.Mode=CMSIS_V1
VP_RTC_VS_RTC_Activate.Mode=RTC_Enabled
VP_RTC_VS_RTC_Alarm_A_Intern.Mode=Alarm A
VP_RTC_VS_RTC_Alarm_B_Intern.Mode=Alarm B
VP_RTC_VS_RTC_Calendar.Mode=RTC_Calendar
VP_STMicroelectronics.X-CUBE-AI_VS_ArtificialOoIntelligenceJjXAaCUBEAaAI_7.3.0_7.3.0.Mode=ArtificialOoIntelligenceJjXAaCUBEAaAI
VP_SYS_VS_tim6.Mode=TIM6
VP_TIM1_VS_ClockSourceINT.Mode=Internal
VP_TIM2_VS_ClockSourceINT.Mode=Internal
VP_TIM3_VS_ClockSourceINT.Mode=Internal
VP_TIM5_VS_ClockSourceINT.Mode=Internal
VP_TIM8_VS_ClockSourceINT.Mode=Internal
VP_USB_HOST_VS_USB_HOST_CDC_FS.Mode=CDC_FS
board=STM32F746G-DISCO

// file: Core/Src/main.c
/* USER CODE BEGIN Header */
/**
  ******************************************************************************
  * @file           : main.c
  * @brief          : Main program body
  ******************************************************************************
  * @attention
  *
  * Copyright (c) 2023 STMicroelectronics.
  * All rights reserved.
  *
  * This software is licensed under terms that can be found in the LICENSE file
  * in the root directory of this software component.
  * If no LICENSE file comes with this software, it is provided AS-IS.
  *
  ******************************************************************************
  */
/* USER CODE END Header */
#include "main.h"
#include "string.h"
#include "cmsis_os.h"
#include "fatfs.h"
#include "usb_host.h"

/* USER CODE BEGIN Includes */

#include "stdio.h"
#include "network_1_data.h"
#include "network_1.h"
#include "ai_platform.h"
#include "ai_datatypes_defines.h"

/* USER CODE END Includes */

#if defined ( __ICCARM__ ) /*!< IAR Compiler */
#pragma location=0x2004c000
ETH_DMADescTypeDef  DMARxDscrTab[ETH_RX_DESC_CNT]; /* Ethernet Rx DMA Descriptors */
#pragma location=0x2004c0a0
ETH_DMADescTypeDef  DMATxDscrTab[ETH_TX_DESC_CNT]; /* Ethernet Tx DMA Descriptors */

#elif defined ( __CC_ARM )  /* MDK ARM Compiler */

__attribute__((at(0x2004c000))) ETH_DMADescTypeDef  DMARxDscrTab[ETH_RX_DESC_CNT]; /* Ethernet Rx DMA Descriptors */
__attribute__((at(0x2004c0a0))) ETH_DMADescTypeDef  DMATxDscrTab[ETH_TX_DESC_CNT]; /* Ethernet Tx DMA Descriptors */

#elif defined ( __GNUC__ ) /* GNU Compiler */
ETH_DMADescTypeDef DMARxDscrTab[ETH_RX_DESC_CNT] __attribute__((section(".RxDecripSection"))); /* Ethernet Rx DMA Descriptors */
ETH_DMADescTypeDef DMATxDscrTab[ETH_TX_DESC_CNT] __attribute__((section(".TxDecripSection")));   /* Ethernet Tx DMA Descriptors */

#endif

ETH_TxPacketConfig TxConfig;

ADC_HandleTypeDef hadc3;

CRC_HandleTypeDef hcrc;

DMA2D_HandleTypeDef hdma2d;

ETH_HandleTypeDef heth;

I2C_HandleTypeDef hi2c1;
I2C_HandleTypeDef hi2c3;

QSPI_HandleTypeDef hqspi;

RTC_HandleTypeDef hrtc;

SAI_HandleTypeDef hsai_BlockA2;
SAI_HandleTypeDef hsai_BlockB2;

SD_HandleTypeDef hsd1;

SPDIFRX_HandleTypeDef hspdif;

SPI_HandleTypeDef hspi2;

TIM_HandleTypeDef htim1;
TIM_HandleTypeDef htim2;
TIM_HandleTypeDef htim3;
TIM_HandleTypeDef htim5;
TIM_HandleTypeDef htim8;
TIM_HandleTypeDef htim12;

UART_HandleTypeDef huart1;
UART_HandleTypeDef huart6;

SDRAM_HandleTypeDef hsdram1;

osThreadId defaultTaskHandle;
/* USER CODE BEGIN PV */
static ai_buffer *ai_input;
static ai_buffer *ai_output;
/* USER CODE END PV */

void SystemClock_Config(void);
void PeriphCommonClock_Config(void);
static void MX_GPIO_Init(void);
static void MX_ADC3_Init(void);
static void MX_CRC_Init(void);
static void MX_DMA2D_Init(void);
static void MX_ETH_Init(void);
static void MX_FMC_Init(void);
static void MX_I2C1_Init(void);
static void MX_I2C3_Init(void);
static void MX_QUADSPI_Init(void);
static void MX_RTC_Init(void);
static void MX_SAI2_Init(void);
static void MX_SDMMC1_SD_Init(void);
static void MX_SPDIFRX_Init(void);
static void MX_SPI2_Init(void);
static void MX_TIM1_Init(void);
static void MX_TIM2_Init(void);
static void MX_TIM3_Init(void);
static void MX_TIM5_Init(void);
static void MX_TIM8_Init(void);
static void MX_TIM12_Init(void);
static void MX_USART1_UART_Init(void);
static void MX_USART6_UART_Init(void);
void StartDefaultTask(void const * argument);

int main(void)
{
  /* USER CODE BEGIN 1 */
	char bur[50];
	char buf[50];
	int buf_len =0;
	ai_error ai_err;
	ai_i32 nbatch;
	uint32_t timestamp;
	float y_val;

			 // Chunk of memory used to hold intermediate values for neural network
/*
		AI_ALIGNED(4) static ai_u8 activations[AI_NETWORK_1_DATA_ACTIVATIONS_SIZE];

		//buffer used to store input  and output tensor

		AI_ALIGNED(4) static ai_u8 in_data[AI_NETWORK_1_IN_1_SIZE_BYTES];
		AI_ALIGNED(4) static ai_u8 out_data[AI_NETWORK_1_OUT_1_SIZE_BYTES];

		//Pointeur to our modele

		ai_handle sine_model = AI_HANDLE_NULL;

		//Initialize wrapper structs that hold pointers to dat and info about the
		//data (tensor height,width, channels)

		ai_buffer ai_input[AI_NETWORK_1_IN_NUM] = AI_NETWORK_1_IN;
		ai_buffer ai_output[AI_NETWORK_1_OUT_NUM] = AI_NETWORK_1_OUT;

		//SEt working memory and get weight from model
		 ai_network_params ai_param = {
				 AI_NETWORK_1_DATA_WEIGHTS(ai_network_1_data_weights_get()),
				 AI_NETWORK_1_DATA_ACTIVATIONS(activations)

		 };
		//set pointers wrapper structs to our data buffers
		 ai_input[0].n_batches = 1;
		 ai_input[0].data = AI_HANDLE_PTR(in_data);
		 ai_output[0].n_batches = 1;
		 ai_output[0].data = AI_HANDLE_PTR(out_data);*/
	// Chunk of memory used to hold the intermediate values for neural network
	    	AI_ALIGNED(4) ai_u32 activations[AI_NETWORK_1_DATA_ACTIVATIONS_SIZE];

	            	// Buffers used to store input and output tensors
	    	AI_ALIGNED(4) ai_u8 in_data[AI_NETWORK_1_IN_1_SIZE_BYTES];
	    	AI_ALIGNED(4) ai_u8 out_data[AI_NETWORK_1_OUT_1_SIZE_BYTES];

	    	// Pointer to our model
	    	ai_handle my_model = AI_HANDLE_NULL;

  /* USER CODE END 1 */

  /* Enable I-Cache---------------------------------------------------------*/
  SCB_EnableICache();

  /* Enable D-Cache---------------------------------------------------------*/
  SCB_EnableDCache();

  /* MCU Configuration--------------------------------------------------------*/

  /* Reset of all peripherals, Initializes the Flash interface and the Systick. */
  HAL_Init();

  /* Configure the system clock */
  SystemClock_Config();

/* Configure the peripherals common clocks */
  PeriphCommonClock_Config();

  /* Initialize all configured peripherals */
  MX_GPIO_Init();
  MX_ADC3_Init();
  MX_CRC_Init();
  MX_DMA2D_Init();
  MX_ETH_Init();
  MX_FMC_Init();
  MX_I2C1_Init();
  MX_I2C3_Init();
  MX_QUADSPI_Init();
  MX_RTC_Init();
  MX_SAI2_Init();
  MX_SDMMC1_SD_Init();
  MX_SPDIFRX_Init();
  MX_SPI2_Init();
  MX_TIM1_Init();
  MX_TIM2_Init();
  MX_TIM3_Init();
  MX_TIM5_Init();
  MX_TIM8_Init();
  MX_TIM12_Init();
  MX_USART1_UART_Init();
  MX_USART6_UART_Init();
  MX_FATFS_Init();
  /* USER CODE BEGIN 2 */

  ai_network_params ai_params =
        {
		  {
				AI_NETWORK_1_DATA_WEIGHTS(ai_network_1_data_weights_get()),
				AI_NETWORK_1_DATA_ACTIVATIONS(activations)
		  }
        };

      // Create instance of the neural network
      ai_err = ai_network_1_create(&my_model, AI_NETWORK_1_DATA_CONFIG);
      if (ai_err.type != AI_ERROR_NONE)
      {
      buf_len = sprintf(buf, "Error: Could not create NN instance\r\n");
	  HAL_UART_Transmit(&huart6, (uint8_t *)buf, buf_len, 100);
	  while(1);
       }
       // Initialize neural network. At this point we are ready to make inferences
       if (!ai_network_1_init(my_model, &ai_params))
       {
	  buf_len = sprintf(buf, "Error: could not initialize NN\r\n");
	  HAL_UART_Transmit(&huart6, (uint8_t *)buf, buf_len, 100);
	  while(1);
        }
        // structs that point to our input and output data and some meta data
  	ai_input = ai_network_1_inputs_get(my_model, NULL);
  	ai_output = ai_network_1_outputs_get(my_model, NULL);
  /* USER CODE END 2 */

  /* Create the thread(s) */
  /* definition and creation of defaultTask */
  osThreadDef(defaultTask, StartDefaultTask, osPriorityNormal, 0, 4096);
  defaultTaskHandle = osThreadCreate(osThread(defaultTask), NULL);

  /* Start scheduler */
  osKernelStart();

  /* We should never get here as control is now taken by the scheduler */
  /* Infinite loop */
  while (1)
  {

    /* USER CODE BEGIN 3 */
	  buf_len = sprintf(buf,"ok\r\n");
	  HAL_UART_Transmit(&huart1,(uint8_t *)buf, buf_len,100);

	  for (uint32_t i=0; i < AI_NETWORK_1_IN_1_SIZE;i++){

	  				((ai_float *)in_data)[i]= (ai_float)2.0f;
	  			}

	  			//timestamp = htim16.Instance ->CNT;

	  			//perform inference

	  			nbatch = ai_network_1_run(my_model,&ai_input[0],&ai_output[0]);
	  			if(nbatch !=1){
	  				buf_len = sprintf(buf,"peut pas run inference\r\n");
	  				HAL_UART_Transmit(&huart1,(uint8_t *)buf, buf_len,100);

	  			}

	  			//read output nn
	  			y_val =((float*)out_data)[0];

	  			buf_len = sprintf(buf,"output: %f",y_val);
	  			HAL_UART_Transmit(&huart1,(uint8_t *)buf, buf_len,100);

	  			HAL_Delay(1000);

  }
  /* USER CODE END 3 */
}

void SystemClock_Config(void)
{
  RCC_OscInitTypeDef RCC_OscInitStruct = {0};
  RCC_ClkInitTypeDef RCC_ClkInitStruct = {0};

  /** Configure LSE Drive Capability
  */
  HAL_PWR_EnableBkUpAccess();

  /** Configure the main internal regulator output voltage
  */
  __HAL_RCC_PWR_CLK_ENABLE();
  __HAL_PWR_VOLTAGESCALING_CONFIG(PWR_REGULATOR_VOLTAGE_SCALE1);

  /** Initializes the RCC Oscillators according to the specified parameters
  * in the RCC_OscInitTypeDef structure.
  */
  RCC_OscInitStruct.OscillatorType = RCC_OSCILLATORTYPE_LSI|RCC_OSCILLATORTYPE_HSE;
  RCC_OscInitStruct.HSEState = RCC_HSE_ON;
  RCC_OscInitStruct.LSIState = RCC_LSI_ON;
  RCC_OscInitStruct.PLL.PLLState = RCC_PLL_ON;
  RCC_OscInitStruct.PLL.PLLSource = RCC_PLLSOURCE_HSE;
  RCC_OscInitStruct.PLL.PLLM = 25;
  RCC_OscInitStruct.PLL.PLLN = 432;
  RCC_OscInitStruct.PLL.PLLP = 2;
  RCC_OscInitStruct.PLL.PLLQ = 9;
  if (HAL_RCC_OscConfig(&RCC_OscInitStruct) != HAL_OK)
  {
    Error_Handler();
  }

  /** Activate the Over-Drive mode
  */
  if (HAL_PWREx_EnableOverDrive() != HAL_OK)
  {
    Error_Handler();
  }

  /** Initializes the CPU, AHB and APB buses clocks
  */
  RCC_ClkInitStruct.ClockType = RCC_CLOCKTYPE_HCLK|RCC_CLOCKTYPE_SYSCLK
                              |RCC_CLOCKTYPE_PCLK1|RCC_CLOCKTYPE_PCLK2;
  RCC_ClkInitStruct.SYSCLKSource = RCC_SYSCLKSOURCE_PLLCLK;
  RCC_ClkInitStruct.AHBCLKDivider = RCC_SYSCLK_DIV1;
  RCC_ClkInitStruct.APB1CLKDivider = RCC_HCLK_DIV4;
  RCC_ClkInitStruct.APB2CLKDivider = RCC_HCLK_DIV2;

  if (HAL_RCC_ClockConfig(&RCC_ClkInitStruct, FLASH_LATENCY_7) != HAL_OK)
  {
    Error_Handler();
  }
}

void PeriphCommonClock_Config(void)
{
  RCC_PeriphCLKInitTypeDef PeriphClkInitStruct = {0};

  /** Initializes the peripherals clock
  */
  PeriphClkInitStruct.PeriphClockSelection = RCC_PERIPHCLK_SAI2|RCC_PERIPHCLK_SDMMC1
                              |RCC_PERIPHCLK_CLK48;
  PeriphClkInitStruct.PLLSAI.PLLSAIN = 384;
  PeriphClkInitStruct.PLLSAI.PLLSAIR = 5;
  PeriphClkInitStruct.PLLSAI.PLLSAIQ = 2;
  PeriphClkInitStruct.PLLSAI.PLLSAIP = RCC_PLLSAIP_DIV8;
  PeriphClkInitStruct.PLLSAIDivQ = 1;
  PeriphClkInitStruct.PLLSAIDivR = RCC_PLLSAIDIVR_8;
  PeriphClkInitStruct.Sai2ClockSelection = RCC_SAI2CLKSOURCE_PLLSAI;
  PeriphClkInitStruct.Clk48ClockSelection = RCC_CLK48SOURCE_PLLSAIP;
  PeriphClkInitStruct.Sdmmc1ClockSelection = RCC_SDMMC1CLKSOURCE_CLK48;
  if (HAL_RCCEx_PeriphCLKConfig(&PeriphClkInitStruct) != HAL_OK)
  {
    Error_Handler();
  }
}

static void MX_ADC3_Init(void)
{

  ADC_ChannelConfTypeDef sConfig = {0};

  /** Configure the global features of the ADC (Clock, Resolution, Data Alignment and number of conversion)
  */
  hadc3.Instance = ADC3;
  hadc3.Init.ClockPrescaler = ADC_CLOCK_SYNC_PCLK_DIV4;
  hadc3.Init.Resolution = ADC_RESOLUTION_12B;
  hadc3.Init.ScanConvMode = ADC_SCAN_DISABLE;
  hadc3.Init.ContinuousConvMode = DISABLE;
  hadc3.Init.DiscontinuousConvMode = DISABLE;
  hadc3.Init.ExternalTrigConvEdge = ADC_EXTERNALTRIGCONVEDGE_NONE;
  hadc3.Init.ExternalTrigConv = ADC_SOFTWARE_START;
  hadc3.Init.DataAlign = ADC_DATAALIGN_RIGHT;
  hadc3.Init.NbrOfConversion = 1;
  hadc3.Init.DMAContinuousRequests = DISABLE;
  hadc3.Init.EOCSelection = ADC_EOC_SINGLE_CONV;
  if (HAL_ADC_Init(&hadc3) != HAL_OK)
  {
    Error_Handler();
  }

  /** Configure for the selected ADC regular channel its corresponding rank in the sequencer and its sample time.
  */
  sConfig.Channel = ADC_CHANNEL_4;
  sConfig.Rank = ADC_REGULAR_RANK_1;
  sConfig.SamplingTime = ADC_SAMPLETIME_3CYCLES;
  if (HAL_ADC_ConfigChannel(&hadc3, &sConfig) != HAL_OK)
  {
    Error_Handler();
  }

}

static void MX_CRC_Init(void)
{

  hcrc.Instance = CRC;
  hcrc.Init.DefaultPolynomialUse = DEFAULT_POLYNOMIAL_ENABLE;
  hcrc.Init.DefaultInitValueUse = DEFAULT_INIT_VALUE_ENABLE;
  hcrc.Init.InputDataInversionMode = CRC_INPUTDATA_INVERSION_NONE;
  hcrc.Init.OutputDataInversionMode = CRC_OUTPUTDATA_INVERSION_DISABLE;
  hcrc.InputDataFormat = CRC_INPUTDATA_FORMAT_BYTES;
  if (HAL_CRC_Init(&hcrc) != HAL_OK)
  {
    Error_Handler();
  }

}

static void MX_DMA2D_Init(void)
{

  hdma2d.Instance = DMA2D;
  hdma2d.Init.Mode = DMA2D_M2M;
  hdma2d.Init.ColorMode = DMA2D_OUTPUT_ARGB8888;
  hdma2d.Init.OutputOffset = 0;
  hdma2d.LayerCfg[1].InputOffset = 0;
  hdma2d.LayerCfg[1].InputColorMode = DMA2D_INPUT_ARGB8888;
  hdma2d.LayerCfg[1].AlphaMode = DMA2D_NO_MODIF_ALPHA;
  hdma2d.LayerCfg[1].InputAlpha = 0;
  if (HAL_DMA2D_Init(&hdma2d) != HAL_OK)
  {
    Error_Handler();
  }
  if (HAL_DMA2D_ConfigLayer(&hdma2d, 1) != HAL_OK)
  {
    Error_Handler();
  }

}

static void MX_ETH_Init(void)
{

   static uint8_t MACAddr[6];

  heth.Instance = ETH;
  MACAddr[0] = 0x00;
  MACAddr[1] = 0x80;
  MACAddr[2] = 0xE1;
  MACAddr[3] = 0x00;
  MACAddr[4] = 0x00;
  MACAddr[5] = 0x00;
  heth.Init.MACAddr = &MACAddr[0];
  heth.Init.MediaInterface = HAL_ETH_RMII_MODE;
  heth.Init.TxDesc = DMATxDscrTab;
  heth.Init.RxDesc = DMARxDscrTab;
  heth.Init.RxBuffLen = 1524;

  if (HAL_ETH_Init(&heth) != HAL_OK)
  {
    Error_Handler();
  }

  memset(&TxConfig, 0 , sizeof(ETH_TxPacketConfig));
  TxConfig.Attributes = ETH_TX_PACKETS_FEATURES_CSUM | ETH_TX_PACKETS_FEATURES_CRCPAD;
  TxConfig.ChecksumCtrl = ETH_CHECKSUM_IPHDR_PAYLOAD_INSERT_PHDR_CALC;
  TxConfig.CRCPadCtrl = ETH_CRC_PAD_INSERT;

}

static void MX_I2C1_Init(void)
{

  hi2c1.Instance = I2C1;
  hi2c1.Init.Timing = 0x20404768;
  hi2c1.Init.OwnAddress1 = 0;
  hi2c1.Init.AddressingMode = I2C_ADDRESSINGMODE_7BIT;
  hi2c1.Init.DualAddressMode = I2C_DUALADDRESS_DISABLE;
  hi2c1.Init.OwnAddress2 = 0;
  hi2c1.Init.OwnAddress2Masks = I2C_OA2_NOMASK;
  hi2c1.Init.GeneralCallMode = I2C_GENERALCALL_DISABLE;
  hi2c1.Init.NoStretchMode = I2C_NOSTRETCH_DISABLE;
  if (HAL_I2C_Init(&hi2c1) != HAL_OK)
  {
    Error_Handler();
  }

  /** Configure Analogue filter
  */
  if (HAL_I2CEx_ConfigAnalogFilter(&hi2c1, I2C_ANALOGFILTER_ENABLE) != HAL_OK)
  {
    Error_Handler();
  }

  /** Configure Digital filter
  */
  if (HAL_I2CEx_ConfigDigitalFilter(&hi2c1, 0) != HAL_OK)
  {
    Error_Handler();
  }

}

static void MX_I2C3_Init(void)
{

  hi2c3.Instance = I2C3;
  hi2c3.Init.Timing = 0x20404768;
  hi2c3.Init.OwnAddress1 = 0;
  hi2c3.Init.AddressingMode = I2C_ADDRESSINGMODE_7BIT;
  hi2c3.Init.DualAddressMode = I2C_DUALADDRESS_DISABLE;
  hi2c3.Init.OwnAddress2 = 0;
  hi2c3.Init.OwnAddress2Masks = I2C_OA2_NOMASK;
  hi2c3.Init.GeneralCallMode = I2C_GENERALCALL_DISABLE;
  hi2c3.Init.NoStretchMode = I2C_NOSTRETCH_DISABLE;
  if (HAL_I2C_Init(&hi2c3) != HAL_OK)
  {
    Error_Handler();
  }

  /** Configure Analogue filter
  */
  if (HAL_I2CEx_ConfigAnalogFilter(&hi2c3, I2C_ANALOGFILTER_ENABLE) != HAL_OK)
  {
    Error_Handler();
  }

  /** Configure Digital filter
  */
  if (HAL_I2CEx_ConfigDigitalFilter(&hi2c3, 0) != HAL_OK)
  {
    Error_Handler();
  }

}

static void MX_QUADSPI_Init(void)
{

  /* QUADSPI parameter configuration*/
  hqspi.Instance = QUADSPI;
  hqspi.Init.ClockPrescaler = 1;
  hqspi.Init.FifoThreshold = 4;
  hqspi.Init.SampleShifting = QSPI_SAMPLE_SHIFTING_HALFCYCLE;
  hqspi.Init.FlashSize = 24;
  hqspi.Init.ChipSelectHighTime = QSPI_CS_HIGH_TIME_6_CYCLE;
  hqspi.Init.ClockMode = QSPI_CLOCK_MODE_0;
  hqspi.Init.FlashID = QSPI_FLASH_ID_1;
  hqspi.Init.DualFlash = QSPI_DUALFLASH_DISABLE;
  if (HAL_QSPI_Init(&hqspi) != HAL_OK)
  {
    Error_Handler();
  }

}

static void MX_RTC_Init(void)
{

  RTC_TimeTypeDef sTime = {0};
  RTC_DateTypeDef sDate = {0};
  RTC_AlarmTypeDef sAlarm = {0};

  /** Initialize RTC Only
  */
  hrtc.Instance = RTC;
  hrtc.Init.HourFormat = RTC_HOURFORMAT_24;
  hrtc.Init.AsynchPrediv = 127;
  hrtc.Init.SynchPrediv = 255;
  hrtc.Init.OutPut = RTC_OUTPUT_DISABLE;
  hrtc.Init.OutPutPolarity = RTC_OUTPUT_POLARITY_HIGH;
  hrtc.Init.OutPutType = RTC_OUTPUT_TYPE_OPENDRAIN;
  if (HAL_RTC_Init(&hrtc) != HAL_OK)
  {
    Error_Handler();
  }

  /** Initialize RTC and set the Time and Date
  */
  sTime.Hours = 0x0;
  sTime.Minutes = 0x0;
  sTime.Seconds = 0x0;
  sTime.DayLightSaving = RTC_DAYLIGHTSAVING_NONE;
  sTime.StoreOperation = RTC_STOREOPERATION_RESET;
  if (HAL_RTC_SetTime(&hrtc, &sTime, RTC_FORMAT_BCD) != HAL_OK)
  {
    Error_Handler();
  }
  sDate.WeekDay = RTC_WEEKDAY_MONDAY;
  sDate.Month = RTC_MONTH_JANUARY;
  sDate.Date = 0x1;
  sDate.Year = 0x0;
  if (HAL_RTC_SetDate(&hrtc, &sDate, RTC_FORMAT_BCD) != HAL_OK)
  {
    Error_Handler();
  }

  /** Enable the Alarm A
  */
  sAlarm.AlarmTime.Hours = 0x0;
  sAlarm.AlarmTime.Minutes = 0x0;
  sAlarm.AlarmTime.Seconds = 0x0;
  sAlarm.AlarmTime.SubSeconds = 0x0;
  sAlarm.AlarmTime.DayLightSaving = RTC_DAYLIGHTSAVING_NONE;
  sAlarm.AlarmTime.StoreOperation = RTC_STOREOPERATION_RESET;
  sAlarm.AlarmMask = RTC_ALARMMASK_NONE;
  sAlarm.AlarmSubSecondMask = RTC_ALARMSUBSECONDMASK_ALL;
  sAlarm.AlarmDateWeekDaySel = RTC_ALARMDATEWEEKDAYSEL_DATE;
  sAlarm.AlarmDateWeekDay = 0x1;
  sAlarm.Alarm = RTC_ALARM_A;
  if (HAL_RTC_SetAlarm(&hrtc, &sAlarm, RTC_FORMAT_BCD) != HAL_OK)
  {
    Error_Handler();
  }

  /** Enable the Alarm B
  */
  sAlarm.Alarm = RTC_ALARM_B;
  if (HAL_RTC_SetAlarm(&hrtc, &sAlarm, RTC_FORMAT_BCD) != HAL_OK)
  {
    Error_Handler();
  }

  /** Enable the TimeStamp
  */
  if (HAL_RTCEx_SetTimeStamp(&hrtc, RTC_TIMESTAMPEDGE_RISING, RTC_TIMESTAMPPIN_POS1) != HAL_OK)
  {
    Error_Handler();
  }

}

static void MX_SAI2_Init(void)
{

  hsai_BlockA2.Instance = SAI2_Block_A;
  hsai_BlockA2.Init.Protocol = SAI_FREE_PROTOCOL;
  hsai_BlockA2.Init.AudioMode = SAI_MODEMASTER_TX;
  hsai_BlockA2.Init.DataSize = SAI_DATASIZE_8;
  hsai_BlockA2.Init.FirstBit = SAI_FIRSTBIT_MSB;
  hsai_BlockA2.Init.ClockStrobing = SAI_CLOCKSTROBING_FALLINGEDGE;
  hsai_BlockA2.Init.Synchro = SAI_ASYNCHRONOUS;
  hsai_BlockA2.Init.OutputDrive = SAI_OUTPUTDRIVE_DISABLE;
  hsai_BlockA2.Init.NoDivider = SAI_MASTERDIVIDER_ENABLE;
  hsai_BlockA2.Init.FIFOThreshold = SAI_FIFOTHRESHOLD_EMPTY;
  hsai_BlockA2.Init.AudioFrequency = SAI_AUDIO_FREQUENCY_192K;
  hsai_BlockA2.Init.SynchroExt = SAI_SYNCEXT_DISABLE;
  hsai_BlockA2.Init.MonoStereoMode = SAI_STEREOMODE;
  hsai_BlockA2.Init.CompandingMode = SAI_NOCOMPANDING;
  hsai_BlockA2.Init.TriState = SAI_OUTPUT_NOTRELEASED;
  hsai_BlockA2.FrameInit.FrameLength = 8;
  hsai_BlockA2.FrameInit.ActiveFrameLength = 1;
  hsai_BlockA2.FrameInit.FSDefinition = SAI_FS_STARTFRAME;
  hsai_BlockA2.FrameInit.FSPolarity = SAI_FS_ACTIVE_LOW;
  hsai_BlockA2.FrameInit.FSOffset = SAI_FS_FIRSTBIT;
  hsai_BlockA2.SlotInit.FirstBitOffset = 0;
  hsai_BlockA2.SlotInit.SlotSize = SAI_SLOTSIZE_DATASIZE;
  hsai_BlockA2.SlotInit.SlotNumber = 1;
  hsai_BlockA2.SlotInit.SlotActive = 0x00000000;
  if (HAL_SAI_Init(&hsai_BlockA2) != HAL_OK)
  {
    Error_Handler();
  }
  hsai_BlockB2.Instance = SAI2_Block_B;
  hsai_BlockB2.Init.Protocol = SAI_FREE_PROTOCOL;
  hsai_BlockB2.Init.AudioMode = SAI_MODESLAVE_RX;
  hsai_BlockB2.Init.DataSize = SAI_DATASIZE_8;
  hsai_BlockB2.Init.FirstBit = SAI_FIRSTBIT_MSB;
  hsai_BlockB2.Init.ClockStrobing = SAI_CLOCKSTROBING_FALLINGEDGE;
  hsai_BlockB2.Init.Synchro = SAI_SYNCHRONOUS;
  hsai_BlockB2.Init.OutputDrive = SAI_OUTPUTDRIVE_DISABLE;
  hsai_BlockB2.Init.FIFOThreshold = SAI_FIFOTHRESHOLD_EMPTY;
  hsai_BlockB2.Init.SynchroExt = SAI_SYNCEXT_DISABLE;
  hsai_BlockB2.Init.MonoStereoMode = SAI_STEREOMODE;
  hsai_BlockB2.Init.CompandingMode = SAI_NOCOMPANDING;
  hsai_BlockB2.Init.TriState = SAI_OUTPUT_NOTRELEASED;
  hsai_BlockB2.FrameInit.FrameLength = 8;
  hsai_BlockB2.FrameInit.ActiveFrameLength = 1;
  hsai_BlockB2.FrameInit.FSDefinition = SAI_FS_STARTFRAME;
  hsai_BlockB2.FrameInit.FSPolarity = SAI_FS_ACTIVE_LOW;
  hsai_BlockB2.FrameInit.FSOffset = SAI_FS_FIRSTBIT;
  hsai_BlockB2.SlotInit.FirstBitOffset = 0;
  hsai_BlockB2.SlotInit.SlotSize = SAI_SLOTSIZE_DATASIZE;
  hsai_BlockB2.SlotInit.SlotNumber = 1;
  hsai_BlockB2.SlotInit.SlotActive = 0x00000000;
  if (HAL_SAI_Init(&hsai_BlockB2) != HAL_OK)
  {
    Error_Handler();
  }

}

static void MX_SDMMC1_SD_Init(void)
{

  hsd1.Instance = SDMMC1;
  hsd1.Init.ClockEdge = SDMMC_CLOCK_EDGE_RISING;
  hsd1.Init.ClockBypass = SDMMC_CLOCK_BYPASS_DISABLE;
  hsd1.Init.ClockPowerSave = SDMMC_CLOCK_POWER_SAVE_DISABLE;
  hsd1.Init.BusWide = SDMMC_BUS_WIDE_4B;
  hsd1.Init.HardwareFlowControl = SDMMC_HARDWARE_FLOW_CONTROL_DISABLE;
  hsd1.Init.ClockDiv = 0;

}

static void MX_SPDIFRX_Init(void)
{

  hspdif.Instance = SPDIFRX;
  hspdif.Init.InputSelection = SPDIFRX_INPUT_IN0;
  hspdif.Init.Retries = SPDIFRX_MAXRETRIES_NONE;
  hspdif.Init.WaitForActivity = SPDIFRX_WAITFORACTIVITY_OFF;
  hspdif.Init.ChannelSelection = SPDIFRX_CHANNEL_A;
  hspdif.Init.DataFormat = SPDIFRX_DATAFORMAT_LSB;
  hspdif.Init.StereoMode = SPDIFRX_STEREOMODE_DISABLE;
  hspdif.Init.PreambleTypeMask = SPDIFRX_PREAMBLETYPEMASK_OFF;
  hspdif.Init.ChannelStatusMask = SPDIFRX_CHANNELSTATUS_OFF;
  hspdif.Init.ValidityBitMask = SPDIFRX_VALIDITYMASK_OFF;
  hspdif.Init.ParityErrorMask = SPDIFRX_PARITYERRORMASK_OFF;
  if (HAL_SPDIFRX_Init(&hspdif) != HAL_OK)
  {
    Error_Handler();
  }

}

static void MX_SPI2_Init(void)
{

  /* SPI2 parameter configuration*/
  hspi2.Instance = SPI2;
  hspi2.Init.Mode = SPI_MODE_MASTER;
  hspi2.Init.Direction = SPI_DIRECTION_2LINES;
  hspi2.Init.DataSize = SPI_DATASIZE_4BIT;
  hspi2.Init.CLKPolarity = SPI_POLARITY_LOW;
  hspi2.Init.CLKPhase = SPI_PHASE_1EDGE;
  hspi2.Init.NSS = SPI_NSS_SOFT;
  hspi2.Init.BaudRatePrescaler = SPI_BAUDRATEPRESCALER_2;
  hspi2.Init.FirstBit = SPI_FIRSTBIT_MSB;
  hspi2.Init.TIMode = SPI_TIMODE_DISABLE;
  hspi2.Init.CRCCalculation = SPI_CRCCALCULATION_DISABLE;
  hspi2.Init.CRCPolynomial = 7;
  hspi2.Init.CRCLength = SPI_CRC_LENGTH_DATASIZE;
  hspi2.Init.NSSPMode = SPI_NSS_PULSE_ENABLE;
  if (HAL_SPI_Init(&hspi2) != HAL_OK)
  {
    Error_Handler();
  }

}

static void MX_TIM1_Init(void)
{

  TIM_ClockConfigTypeDef sClockSourceConfig = {0};
  TIM_MasterConfigTypeDef sMasterConfig = {0};
  TIM_OC_InitTypeDef sConfigOC = {0};
  TIM_BreakDeadTimeConfigTypeDef sBreakDeadTimeConfig = {0};

  htim1.Instance = TIM1;
  htim1.Init.Prescaler = 0;
  htim1.Init.CounterMode = TIM_COUNTERMODE_UP;
  htim1.Init.Period = 65535;
  htim1.Init.ClockDivision = TIM_CLOCKDIVISION_DIV1;
  htim1.Init.RepetitionCounter = 0;
  htim1.Init.AutoReloadPreload = TIM_AUTORELOAD_PRELOAD_DISABLE;
  if (HAL_TIM_Base_Init(&htim1) != HAL_OK)
  {
    Error_Handler();
  }
  sClockSourceConfig.ClockSource = TIM_CLOCKSOURCE_INTERNAL;
  if (HAL_TIM_ConfigClockSource(&htim1, &sClockSourceConfig) != HAL_OK)
  {
    Error_Handler();
  }
  if (HAL_TIM_PWM_Init(&htim1) != HAL_OK)
  {
    Error_Handler();
  }
  sMasterConfig.MasterOutputTrigger = TIM_TRGO_RESET;
  sMasterConfig.MasterOutputTrigger2 = TIM_TRGO2_RESET;
  sMasterConfig.MasterSlaveMode = TIM_MASTERSLAVEMODE_DISABLE;
  if (HAL_TIMEx_MasterConfigSynchronization(&htim1, &sMasterConfig) != HAL_OK)
  {
    Error_Handler();
  }
  sConfigOC.OCMode = TIM_OCMODE_PWM1;
  sConfigOC.Pulse = 0;
  sConfigOC.OCPolarity = TIM_OCPOLARITY_HIGH;
  sConfigOC.OCNPolarity = TIM_OCNPOLARITY_HIGH;
  sConfigOC.OCFastMode = TIM_OCFAST_DISABLE;
  sConfigOC.OCIdleState = TIM_OCIDLESTATE_RESET;
  sConfigOC.OCNIdleState = TIM_OCNIDLESTATE_RESET;
  if (HAL_TIM_PWM_ConfigChannel(&htim1, &sConfigOC, TIM_CHANNEL_1) != HAL_OK)
  {
    Error_Handler();
  }
  sBreakDeadTimeConfig.OffStateRunMode = TIM_OSSR_DISABLE;
  sBreakDeadTimeConfig.OffStateIDLEMode = TIM_OSSI_DISABLE;
  sBreakDeadTimeConfig.LockLevel = TIM_LOCKLEVEL_OFF;
  sBreakDeadTimeConfig.DeadTime = 0;
  sBreakDeadTimeConfig.BreakState = TIM_BREAK_DISABLE;
  sBreakDeadTimeConfig.BreakPolarity = TIM_BREAKPOLARITY_HIGH;
  sBreakDeadTimeConfig.BreakFilter = 0;
  sBreakDeadTimeConfig.Break2State = TIM_BREAK2_DISABLE;
  sBreakDeadTimeConfig.Break2Polarity = TIM_BREAK2POLARITY_HIGH;
  sBreakDeadTimeConfig.Break2Filter = 0;
  sBreakDeadTimeConfig.AutomaticOutput = TIM_AUTOMATICOUTPUT_DISABLE;
  if (HAL_TIMEx_ConfigBreakDeadTime(&htim1, &sBreakDeadTimeConfig) != HAL_OK)
  {
    Error_Handler();
  }
  HAL_TIM_MspPostInit(&htim1);

}

static void MX_TIM2_Init(void)
{

  TIM_ClockConfigTypeDef sClockSourceConfig = {0};
  TIM_MasterConfigTypeDef sMasterConfig = {0};
  TIM_OC_InitTypeDef sConfigOC = {0};

  htim2.Instance = TIM2;
  htim2.Init.Prescaler = 0;
  htim2.Init.CounterMode = TIM_COUNTERMODE_UP;
  htim2.Init.Period = 4294967295;
  htim2.Init.ClockDivision = TIM_CLOCKDIVISION_DIV1;
  htim2.Init.AutoReloadPreload = TIM_AUTORELOAD_PRELOAD_DISABLE;
  if (HAL_TIM_Base_Init(&htim2) != HAL_OK)
  {
    Error_Handler();
  }
  sClockSourceConfig.ClockSource = TIM_CLOCKSOURCE_INTERNAL;
  if (HAL_TIM_ConfigClockSource(&htim2, &sClockSourceConfig) != HAL_OK)
  {
    Error_Handler();
  }
  if (HAL_TIM_PWM_Init(&htim2) != HAL_OK)
  {
    Error_Handler();
  }
  sMasterConfig.MasterOutputTrigger = TIM_TRGO_RESET;
  sMasterConfig.MasterSlaveMode = TIM_MASTERSLAVEMODE_DISABLE;
  if (HAL_TIMEx_MasterConfigSynchronization(&htim2, &sMasterConfig) != HAL_OK)
  {
    Error_Handler();
  }
  sConfigOC.OCMode = TIM_OCMODE_PWM1;
  sConfigOC.Pulse = 0;
  sConfigOC.OCPolarity = TIM_OCPOLARITY_HIGH;
  sConfigOC.OCFastMode = TIM_OCFAST_DISABLE;
  if (HAL_TIM_PWM_ConfigChannel(&htim2, &sConfigOC, TIM_CHANNEL_1) != HAL_OK)
  {
    Error_Handler();
  }
  HAL_TIM_MspPostInit(&htim2);

}

static void MX_TIM3_Init(void)
{

  TIM_ClockConfigTypeDef sClockSourceConfig = {0};
  TIM_MasterConfigTypeDef sMasterConfig = {0};
  TIM_OC_InitTypeDef sConfigOC = {0};

  htim3.Instance = TIM3;
  htim3.Init.Prescaler = 0;
  htim3.Init.CounterMode = TIM_COUNTERMODE_UP;
  htim3.Init.Period = 65535;
  htim3.Init.ClockDivision = TIM_CLOCKDIVISION_DIV1;
  htim3.Init.AutoReloadPreload = TIM_AUTORELOAD_PRELOAD_DISABLE;
  if (HAL_TIM_Base_Init(&htim3) != HAL_OK)
  {
    Error_Handler();
  }
  sClockSourceConfig.ClockSource = TIM_CLOCKSOURCE_INTERNAL;
  if (HAL_TIM_ConfigClockSource(&htim3, &sClockSourceConfig) != HAL_OK)
  {
    Error_Handler();
  }
  if (HAL_TIM_PWM_Init(&htim3) != HAL_OK)
  {
    Error_Handler();
  }
  sMasterConfig.MasterOutputTrigger = TIM_TRGO_RESET;
  sMasterConfig.MasterSlaveMode = TIM_MASTERSLAVEMODE_DISABLE;
  if (HAL_TIMEx_MasterConfigSynchronization(&htim3, &sMasterConfig) != HAL_OK)
  {
    Error_Handler();
  }
  sConfigOC.OCMode = TIM_OCMODE_PWM1;
  sConfigOC.Pulse = 0;
  sConfigOC.OCPolarity = TIM_OCPOLARITY_HIGH;
  sConfigOC.OCFastMode = TIM_OCFAST_DISABLE;
  if (HAL_TIM_PWM_ConfigChannel(&htim3, &sConfigOC, TIM_CHANNEL_1) != HAL_OK)
  {
    Error_Handler();
  }
  HAL_TIM_MspPostInit(&htim3);

}

static void MX_TIM5_Init(void)
{

  TIM_ClockConfigTypeDef sClockSourceConfig = {0};
  TIM_MasterConfigTypeDef sMasterConfig = {0};
  TIM_OC_InitTypeDef sConfigOC = {0};

  htim5.Instance = TIM5;
  htim5.Init.Prescaler = 0;
  htim5.Init.CounterMode = TIM_COUNTERMODE_UP;
  htim5.Init.Period = 4294967295;
  htim5.Init.ClockDivision = TIM_CLOCKDIVISION_DIV1;
  htim5.Init.AutoReloadPreload = TIM_AUTORELOAD_PRELOAD_DISABLE;
  if (HAL_TIM_Base_Init(&htim5) != HAL_OK)
  {
    Error_Handler();
  }
  sClockSourceConfig.ClockSource = TIM_CLOCKSOURCE_INTERNAL;
  if (HAL_TIM_ConfigClockSource(&htim5, &sClockSourceConfig) != HAL_OK)
  {
    Error_Handler();
  }
  if (HAL_TIM_PWM_Init(&htim5) != HAL_OK)
  {
    Error_Handler();
  }
  sMasterConfig.MasterOutputTrigger = TIM_TRGO_RESET;
  sMasterConfig.MasterSlaveMode = TIM_MASTERSLAVEMODE_DISABLE;
  if (HAL_TIMEx_MasterConfigSynchronization(&htim5, &sMasterConfig) != HAL_OK)
  {
    Error_Handler();
  }
  sConfigOC.OCMode = TIM_OCMODE_PWM1;
  sConfigOC.Pulse = 0;
  sConfigOC.OCPolarity = TIM_OCPOLARITY_HIGH;
  sConfigOC.OCFastMode = TIM_OCFAST_DISABLE;
  if (HAL_TIM_PWM_ConfigChannel(&htim5, &sConfigOC, TIM_CHANNEL_4) != HAL_OK)
  {
    Error_Handler();
  }
  HAL_TIM_MspPostInit(&htim5);

}

static void MX_TIM8_Init(void)
{

  TIM_ClockConfigTypeDef sClockSourceConfig = {0};
  TIM_MasterConfigTypeDef sMasterConfig = {0};

  htim8.Instance = TIM8;
  htim8.Init.Prescaler = 0;
  htim8.Init.CounterMode = TIM_COUNTERMODE_UP;
  htim8.Init.Period = 65535;
  htim8.Init.ClockDivision = TIM_CLOCKDIVISION_DIV1;
  htim8.Init.RepetitionCounter = 0;
  htim8.Init.AutoReloadPreload = TIM_AUTORELOAD_PRELOAD_DISABLE;
  if (HAL_TIM_Base_Init(&htim8) != HAL_OK)
  {
    Error_Handler();
  }
  sClockSourceConfig.ClockSource = TIM_CLOCKSOURCE_INTERNAL;
  if (HAL_TIM_ConfigClockSource(&htim8, &sClockSourceConfig) != HAL_OK)
  {
    Error_Handler();
  }
  sMasterConfig.MasterOutputTrigger = TIM_TRGO_RESET;
  sMasterConfig.MasterOutputTrigger2 = TIM_TRGO2_RESET;
  sMasterConfig.MasterSlaveMode = TIM_MASTERSLAVEMODE_DISABLE;
  if (HAL_TIMEx_MasterConfigSynchronization(&htim8, &sMasterConfig) != HAL_OK)
  {
    Error_Handler();
  }

}

static void MX_TIM12_Init(void)
{

  TIM_OC_InitTypeDef sConfigOC = {0};

  htim12.Instance = TIM12;
  htim12.Init.Prescaler = 0;
  htim12.Init.CounterMode = TIM_COUNTERMODE_UP;
  htim12.Init.Period = 65535;
  htim12.Init.ClockDivision = TIM_CLOCKDIVISION_DIV1;
  htim12.Init.AutoReloadPreload = TIM_AUTORELOAD_PRELOAD_DISABLE;
  if (HAL_TIM_PWM_Init(&htim12) != HAL_OK)
  {
    Error_Handler();
  }
  sConfigOC.OCMode = TIM_OCMODE_PWM1;
  sConfigOC.Pulse = 0;
  sConfigOC.OCPolarity = TIM_OCPOLARITY_HIGH;
  sConfigOC.OCFastMode = TIM_OCFAST_DISABLE;
  if (HAL_TIM_PWM_ConfigChannel(&htim12, &sConfigOC, TIM_CHANNEL_1) != HAL_OK)
  {
    Error_Handler();
  }
  HAL_TIM_MspPostInit(&htim12);

}

static void MX_USART1_UART_Init(void)
{

  huart1.Instance = USART1;
  huart1.Init.BaudRate = 115200;
  huart1.Init.WordLength = UART_WORDLENGTH_8B;
  huart1.Init.StopBits = UART_STOPBITS_1;
  huart1.Init.Parity = UART_PARITY_NONE;
  huart1.Init.Mode = UART_MODE_TX_RX;
  huart1.Init.HwFlowCtl = UART_HWCONTROL_NONE;
  huart1.Init.OverSampling = UART_OVERSAMPLING_16;
  huart1.Init.OneBitSampling = UART_ONE_BIT_SAMPLE_DISABLE;
  huart1.AdvancedInit.AdvFeatureInit = UART_ADVFEATURE_NO_INIT;
  if (HAL_UART_Init(&huart1) != HAL_OK)
  {
    Error_Handler();
  }

}

static void MX_USART6_UART_Init(void)
{

  huart6.Instance = USART6;
  huart6.Init.BaudRate = 115200;
  huart6.Init.WordLength = UART_WORDLENGTH_8B;
  huart6.Init.StopBits = UART_STOPBITS_1;
  huart6.Init.Parity = UART_PARITY_NONE;
  huart6.Init.Mode = UART_MODE_TX_RX;
  huart6.Init.HwFlowCtl = UART_HWCONTROL_NONE;
  huart6.Init.OverSampling = UART_OVERSAMPLING_16;
  huart6.Init.OneBitSampling = UART_ONE_BIT_SAMPLE_DISABLE;
  huart6.AdvancedInit.AdvFeatureInit = UART_ADVFEATURE_NO_INIT;
  if (HAL_UART_Init(&huart6) != HAL_OK)
  {
    Error_Handler();
  }

}

/* FMC initialization function */
static void MX_FMC_Init(void)
{

  FMC_SDRAM_TimingTypeDef SdramTiming = {0};

  /** Perform the SDRAM1 memory initialization sequence
  */
  hsdram1.Instance = FMC_SDRAM_DEVICE;
  /* hsdram1.Init */
  hsdram1.Init.SDBank = FMC_SDRAM_BANK1;
  hsdram1.Init.ColumnBitsNumber = FMC_SDRAM_COLUMN_BITS_NUM_8;
  hsdram1.Init.RowBitsNumber = FMC_SDRAM_ROW_BITS_NUM_12;
  hsdram1.Init.MemoryDataWidth = FMC_SDRAM_MEM_BUS_WIDTH_16;
  hsdram1.Init.InternalBankNumber = FMC_SDRAM_INTERN_BANKS_NUM_4;
  hsdram1.Init.CASLatency = FMC_SDRAM_CAS_LATENCY_3;
  hsdram1.Init.WriteProtection = FMC_SDRAM_WRITE_PROTECTION_DISABLE;
  hsdram1.Init.SDClockPeriod = FMC_SDRAM_CLOCK_PERIOD_2;
  hsdram1.Init.ReadBurst = FMC_SDRAM_RBURST_ENABLE;
  hsdram1.Init.ReadPipeDelay = FMC_SDRAM_RPIPE_DELAY_0;
  /* SdramTiming */
  SdramTiming.LoadToActiveDelay = 2;
  SdramTiming.ExitSelfRefreshDelay = 7;
  SdramTiming.SelfRefreshTime = 4;
  SdramTiming.RowCycleDelay = 7;
  SdramTiming.WriteRecoveryTime = 3;
  SdramTiming.RPDelay = 2;
  SdramTiming.RCDDelay = 2;

  if (HAL_SDRAM_Init(&hsdram1, &SdramTiming) != HAL_OK)
  {
    Error_Handler( );
  }

}

static void MX_GPIO_Init(void)
{
  GPIO_InitTypeDef GPIO_InitStruct = {0};

  /* GPIO Ports Clock Enable */
  __HAL_RCC_GPIOE_CLK_ENABLE();
  __HAL_RCC_GPIOG_CLK_ENABLE();
  __HAL_RCC_GPIOB_CLK_ENABLE();
  __HAL_RCC_GPIOD_CLK_ENABLE();
  __HAL_RCC_GPIOC_CLK_ENABLE();
  __HAL_RCC_GPIOA_CLK_ENABLE();
  __HAL_RCC_GPIOJ_CLK_ENABLE();
  __HAL_RCC_GPIOI_CLK_ENABLE();
  __HAL_RCC_GPIOK_CLK_ENABLE();
  __HAL_RCC_GPIOF_CLK_ENABLE();
  __HAL_RCC_GPIOH_CLK_ENABLE();

  /*Configure GPIO pin Output Level */
  HAL_GPIO_WritePin(OTG_FS_PowerSwitchOn_GPIO_Port, OTG_FS_PowerSwitchOn_Pin, GPIO_PIN_SET);

  /*Configure GPIO pin Output Level */
  HAL_GPIO_WritePin(GPIOI, ARDUINO_D7_Pin|ARDUINO_D8_Pin, GPIO_PIN_RESET);

  /*Configure GPIO pin Output Level */
  HAL_GPIO_WritePin(LCD_BL_CTRL_GPIO_Port, LCD_BL_CTRL_Pin, GPIO_PIN_SET);

  /*Configure GPIO pin Output Level */
  HAL_GPIO_WritePin(LCD_DISP_GPIO_Port, LCD_DISP_Pin, GPIO_PIN_SET);

  /*Configure GPIO pin Output Level */
  HAL_GPIO_WritePin(DCMI_PWR_EN_GPIO_Port, DCMI_PWR_EN_Pin, GPIO_PIN_RESET);

  /*Configure GPIO pin Output Level */
  HAL_GPIO_WritePin(GPIOG, ARDUINO_D4_Pin|ARDUINO_D2_Pin|EXT_RST_Pin, GPIO_PIN_RESET);

  /*Configure GPIO pin : LCD_B0_Pin */
  GPIO_InitStruct.Pin = LCD_B0_Pin;
  GPIO_InitStruct.Mode = GPIO_MODE_AF_PP;
  GPIO_InitStruct.Pull = GPIO_NOPULL;
  GPIO_InitStruct.Speed = GPIO_SPEED_FREQ_LOW;
  GPIO_InitStruct.Alternate = GPIO_AF14_LTDC;
  HAL_GPIO_Init(LCD_B0_GPIO_Port, &GPIO_InitStruct);

  /*Configure GPIO pin : OTG_HS_OverCurrent_Pin */
  GPIO_InitStruct.Pin = OTG_HS_OverCurrent_Pin;
  GPIO_InitStruct.Mode = GPIO_MODE_INPUT;
  GPIO_InitStruct.Pull = GPIO_NOPULL;
  HAL_GPIO_Init(OTG_HS_OverCurrent_GPIO_Port, &GPIO_InitStruct);

  /*Configure GPIO pins : ULPI_D7_Pin ULPI_D6_Pin ULPI_D5_Pin ULPI_D3_Pin
                           ULPI_D2_Pin ULPI_D1_Pin ULPI_D4_Pin */
  GPIO_InitStruct.Pin = ULPI_D7_Pin|ULPI_D6_Pin|ULPI_D5_Pin|ULPI_D3_Pin
                          |ULPI_D2_Pin|ULPI_D1_Pin|ULPI_D4_Pin;
  GPIO_InitStruct.Mode = GPIO_MODE_AF_PP;
  GPIO_InitStruct.Pull = GPIO_NOPULL;
  GPIO_InitStruct.Speed = GPIO_SPEED_FREQ_VERY_HIGH;
  GPIO_InitStruct.Alternate = GPIO_AF10_OTG_HS;
  HAL_GPIO_Init(GPIOB, &GPIO_InitStruct);

  /*Configure GPIO pins : DCMI_D6_Pin DCMI_D7_Pin */
  GPIO_InitStruct.Pin = DCMI_D6_Pin|DCMI_D7_Pin;
  GPIO_InitStruct.Mode = GPIO_MODE_AF_PP;
  GPIO_InitStruct.Pull = GPIO_NOPULL;
  GPIO_InitStruct.Speed = GPIO_SPEED_FREQ_LOW;
  GPIO_InitStruct.Alternate = GPIO_AF13_DCMI;
  HAL_GPIO_Init(GPIOE, &GPIO_InitStruct);

  /*Configure GPIO pins : LCD_B1_Pin LCD_B2_Pin LCD_B3_Pin LCD_G4_Pin
                           LCD_G1_Pin LCD_G3_Pin LCD_G0_Pin LCD_G2_Pin
                           LCD_R7_Pin LCD_R5_Pin LCD_R6_Pin LCD_R4_Pin
                           LCD_R3_Pin LCD_R1_Pin LCD_R2_Pin */
  GPIO_InitStruct.Pin = LCD_B1_Pin|LCD_B2_Pin|LCD_B3_Pin|LCD_G4_Pin
                          |LCD_G1_Pin|LCD_G3_Pin|LCD_G0_Pin|LCD_G2_Pin
                          |LCD_R7_Pin|LCD_R5_Pin|LCD_R6_Pin|LCD_R4_Pin
                          |LCD_R3_Pin|LCD_R1_Pin|LCD_R2_Pin;
  GPIO_InitStruct.Mode = GPIO_MODE_AF_PP;
  GPIO_InitStruct.Pull = GPIO_NOPULL;
  GPIO_InitStruct.Speed = GPIO_SPEED_FREQ_LOW;
  GPIO_InitStruct.Alternate = GPIO_AF14_LTDC;
  HAL_GPIO_Init(GPIOJ, &GPIO_InitStruct);

  /*Configure GPIO pin : OTG_FS_VBUS_Pin */
  GPIO_InitStruct.Pin = OTG_FS_VBUS_Pin;
  GPIO_InitStruct.Mode = GPIO_MODE_INPUT;
  GPIO_InitStruct.Pull = GPIO_NOPULL;
  HAL_GPIO_Init(OTG_FS_VBUS_GPIO_Port, &GPIO_InitStruct);

  /*Configure GPIO pin : Audio_INT_Pin */
  GPIO_InitStruct.Pin = Audio_INT_Pin;
  GPIO_InitStruct.Mode = GPIO_MODE_EVT_RISING;
  GPIO_InitStruct.Pull = GPIO_NOPULL;
  HAL_GPIO_Init(Audio_INT_GPIO_Port, &GPIO_InitStruct);

  /*Configure GPIO pins : LCD_DE_Pin LCD_B7_Pin LCD_B6_Pin LCD_B5_Pin
                           LCD_G6_Pin LCD_G7_Pin LCD_G5_Pin */
  GPIO_InitStruct.Pin = LCD_DE_Pin|LCD_B7_Pin|LCD_B6_Pin|LCD_B5_Pin
                          |LCD_G6_Pin|LCD_G7_Pin|LCD_G5_Pin;
  GPIO_InitStruct.Mode = GPIO_MODE_AF_PP;
  GPIO_InitStruct.Pull = GPIO_NOPULL;
  GPIO_InitStruct.Speed = GPIO_SPEED_FREQ_LOW;
  GPIO_InitStruct.Alternate = GPIO_AF14_LTDC;
  HAL_GPIO_Init(GPIOK, &GPIO_InitStruct);

  /*Configure GPIO pin : LCD_B4_Pin */
  GPIO_InitStruct.Pin = LCD_B4_Pin;
  GPIO_InitStruct.Mode = GPIO_MODE_AF_PP;
  GPIO_InitStruct.Pull = GPIO_NOPULL;
  GPIO_InitStruct.Speed = GPIO_SPEED_FREQ_LOW;
  GPIO_InitStruct.Alternate = GPIO_AF9_LTDC;
  HAL_GPIO_Init(LCD_B4_GPIO_Port, &GPIO_InitStruct);

  /*Configure GPIO pin : OTG_FS_PowerSwitchOn_Pin */
  GPIO_InitStruct.Pin = OTG_FS_PowerSwitchOn_Pin;
  GPIO_InitStruct.Mode = GPIO_MODE_OUTPUT_PP;
  GPIO_InitStruct.Pull = GPIO_NOPULL;
  GPIO_InitStruct.Speed = GPIO_SPEED_FREQ_LOW;
  HAL_GPIO_Init(OTG_FS_PowerSwitchOn_GPIO_Port, &GPIO_InitStruct);

  /*Configure GPIO pin : DCMI_D5_Pin */
  GPIO_InitStruct.Pin = DCMI_D5_Pin;
  GPIO_InitStruct.Mode = GPIO_MODE_AF_PP;
  GPIO_InitStruct.Pull = GPIO_NOPULL;
  GPIO_InitStruct.Speed = GPIO_SPEED_FREQ_LOW;
  GPIO_InitStruct.Alternate = GPIO_AF13_DCMI;
  HAL_GPIO_Init(DCMI_D5_GPIO_Port, &GPIO_InitStruct);

  /*Configure GPIO pins : ARDUINO_D7_Pin ARDUINO_D8_Pin LCD_DISP_Pin */
  GPIO_InitStruct.Pin = ARDUINO_D7_Pin|ARDUINO_D8_Pin|LCD_DISP_Pin;
  GPIO_InitStruct.Mode = GPIO_MODE_OUTPUT_PP;
  GPIO_InitStruct.Pull = GPIO_NOPULL;
  GPIO_InitStruct.Speed = GPIO_SPEED_FREQ_LOW;
  HAL_GPIO_Init(GPIOI, &GPIO_InitStruct);

  /*Configure GPIO pin : uSD_Detect_Pin */
  GPIO_InitStruct.Pin = uSD_Detect_Pin;
  GPIO_InitStruct.Mode = GPIO_MODE_INPUT;
  GPIO_InitStruct.Pull = GPIO_NOPULL;
  HAL_GPIO_Init(uSD_Detect_GPIO_Port, &GPIO_InitStruct);

  /*Configure GPIO pins : LCD_HSYNC_Pin LCD_VSYNC_Pin LCD_R0_Pin LCD_CLK_Pin */
  GPIO_InitStruct.Pin = LCD_HSYNC_Pin|LCD_VSYNC_Pin|LCD_R0_Pin|LCD_CLK_Pin;
  GPIO_InitStruct.Mode = GPIO_MODE_AF_PP;
  GPIO_InitStruct.Pull = GPIO_NOPULL;
  GPIO_InitStruct.Speed = GPIO_SPEED_FREQ_LOW;
  GPIO_InitStruct.Alternate = GPIO_AF14_LTDC;
  HAL_GPIO_Init(GPIOI, &GPIO_InitStruct);

  /*Configure GPIO pin : LCD_BL_CTRL_Pin */
  GPIO_InitStruct.Pin = LCD_BL_CTRL_Pin;
  GPIO_InitStruct.Mode = GPIO_MODE_OUTPUT_PP;
  GPIO_InitStruct.Pull = GPIO_NOPULL;
  GPIO_InitStruct.Speed = GPIO_SPEED_FREQ_LOW;
  HAL_GPIO_Init(LCD_BL_CTRL_GPIO_Port, &GPIO_InitStruct);

  /*Configure GPIO pin : DCMI_VSYNC_Pin */
  GPIO_InitStruct.Pin = DCMI_VSYNC_Pin;
  GPIO_InitStruct.Mode = GPIO_MODE_AF_PP;
  GPIO_InitStruct.Pull = GPIO_NOPULL;
  GPIO_InitStruct.Speed = GPIO_SPEED_FREQ_LOW;
  GPIO_InitStruct.Alternate = GPIO_AF13_DCMI;
  HAL_GPIO_Init(DCMI_VSYNC_GPIO_Port, &GPIO_InitStruct);

  /*Configure GPIO pin : OTG_FS_OverCurrent_Pin */
  GPIO_InitStruct.Pin = OTG_FS_OverCurrent_Pin;
  GPIO_InitStruct.Mode = GPIO_MODE_INPUT;
  GPIO_InitStruct.Pull = GPIO_NOPULL;
  HAL_GPIO_Init(OTG_FS_OverCurrent_GPIO_Port, &GPIO_InitStruct);

  /*Configure GPIO pins : TP3_Pin NC2_Pin */
  GPIO_InitStruct.Pin = TP3_Pin|NC2_Pin;
  GPIO_InitStruct.Mode = GPIO_MODE_INPUT;
  GPIO_InitStruct.Pull = GPIO_NOPULL;
  HAL_GPIO_Init(GPIOH, &GPIO_InitStruct);

  /*Configure GPIO pin : DCMI_PWR_EN_Pin */
  GPIO_InitStruct.Pin = DCMI_PWR_EN_Pin;
  GPIO_InitStruct.Mode = GPIO_MODE_OUTPUT_PP;
  GPIO_InitStruct.Pull = GPIO_NOPULL;
  GPIO_InitStruct.Speed = GPIO_SPEED_FREQ_LOW;
  HAL_GPIO_Init(DCMI_PWR_EN_GPIO_Port, &GPIO_InitStruct);

  /*Configure GPIO pins : DCMI_D4_Pin DCMI_D3_Pin DCMI_D0_Pin DCMI_D2_Pin
                           DCMI_D1_Pin */
  GPIO_InitStruct.Pin = DCMI_D4_Pin|DCMI_D3_Pin|DCMI_D0_Pin|DCMI_D2_Pin
                          |DCMI_D1_Pin;
  GPIO_InitStruct.Mode = GPIO_MODE_AF_PP;
  GPIO_InitStruct.Pull = GPIO_NOPULL;
  GPIO_InitStruct.Speed = GPIO_SPEED_FREQ_LOW;
  GPIO_InitStruct.Alternate = GPIO_AF13_DCMI;
  HAL_GPIO_Init(GPIOH, &GPIO_InitStruct);

  /*Configure GPIO pin : LCD_INT_Pin */
  GPIO_InitStruct.Pin = LCD_INT_Pin;
  GPIO_InitStruct.Mode = GPIO_MODE_EVT_RISING;
  GPIO_InitStruct.Pull = GPIO_NOPULL;
  HAL_GPIO_Init(LCD_INT_GPIO_Port, &GPIO_InitStruct);

  /*Configure GPIO pin : ULPI_NXT_Pin */
  GPIO_InitStruct.Pin = ULPI_NXT_Pin;
  GPIO_InitStruct.Mode = GPIO_MODE_AF_PP;
  GPIO_InitStruct.Pull = GPIO_NOPULL;
  GPIO_InitStruct.Speed = GPIO_SPEED_FREQ_VERY_HIGH;
  GPIO_InitStruct.Alternate = GPIO_AF10_OTG_HS;
  HAL_GPIO_Init(ULPI_NXT_GPIO_Port, &GPIO_InitStruct);

  /*Configure GPIO pins : ARDUINO_D4_Pin ARDUINO_D2_Pin EXT_RST_Pin */
  GPIO_InitStruct.Pin = ARDUINO_D4_Pin|ARDUINO_D2_Pin|EXT_RST_Pin;
  GPIO_InitStruct.Mode = GPIO_MODE_OUTPUT_PP;
  GPIO_InitStruct.Pull = GPIO_NOPULL;
  GPIO_InitStruct.Speed = GPIO_SPEED_FREQ_LOW;
  HAL_GPIO_Init(GPIOG, &GPIO_InitStruct);

  /*Configure GPIO pins : ULPI_STP_Pin ULPI_DIR_Pin */
  GPIO_InitStruct.Pin = ULPI_STP_Pin|ULPI_DIR_Pin;
  GPIO_InitStruct.Mode = GPIO_MODE_AF_PP;
  GPIO_InitStruct.Pull = GPIO_NOPULL;
  GPIO_InitStruct.Speed = GPIO_SPEED_FREQ_VERY_HIGH;
  GPIO_InitStruct.Alternate = GPIO_AF10_OTG_HS;
  HAL_GPIO_Init(GPIOC, &GPIO_InitStruct);

  /*Configure GPIO pin : RMII_RXER_Pin */
  GPIO_InitStruct.Pin = RMII_RXER_Pin;
  GPIO_InitStruct.Mode = GPIO_MODE_INPUT;
  GPIO_InitStruct.Pull = GPIO_NOPULL;
  HAL_GPIO_Init(RMII_RXER_GPIO_Port, &GPIO_InitStruct);

  /*Configure GPIO pins : DCMI_HSYNC_Pin PA6 */
  GPIO_InitStruct.Pin = DCMI_HSYNC_Pin|GPIO_PIN_6;
  GPIO_InitStruct.Mode = GPIO_MODE_AF_PP;
  GPIO_InitStruct.Pull = GPIO_NOPULL;
  GPIO_InitStruct.Speed = GPIO_SPEED_FREQ_LOW;
  GPIO_InitStruct.Alternate = GPIO_AF13_DCMI;
  HAL_GPIO_Init(GPIOA, &GPIO_InitStruct);

  /*Configure GPIO pins : ULPI_CLK_Pin ULPI_D0_Pin */
  GPIO_InitStruct.Pin = ULPI_CLK_Pin|ULPI_D0_Pin;
  GPIO_InitStruct.Mode = GPIO_MODE_AF_PP;
  GPIO_InitStruct.Pull = GPIO_NOPULL;
  GPIO_InitStruct.Speed = GPIO_SPEED_FREQ_VERY_HIGH;
  GPIO_InitStruct.Alternate = GPIO_AF10_OTG_HS;
  HAL_GPIO_Init(GPIOA, &GPIO_InitStruct);

}

void StartDefaultTask(void const * argument)
{
  /* init code for USB_HOST */
  MX_USB_HOST_Init();
  for(;;)
  {
    osDelay(1);
  }
}

void HAL_TIM_PeriodElapsedCallback(TIM_HandleTypeDef *htim)
{
  if (htim->Instance == TIM6) {
    HAL_IncTick();
  }
}

void Error_Handler(void)
{
  __disable_irq();
  while (1)
  {
  }
}
